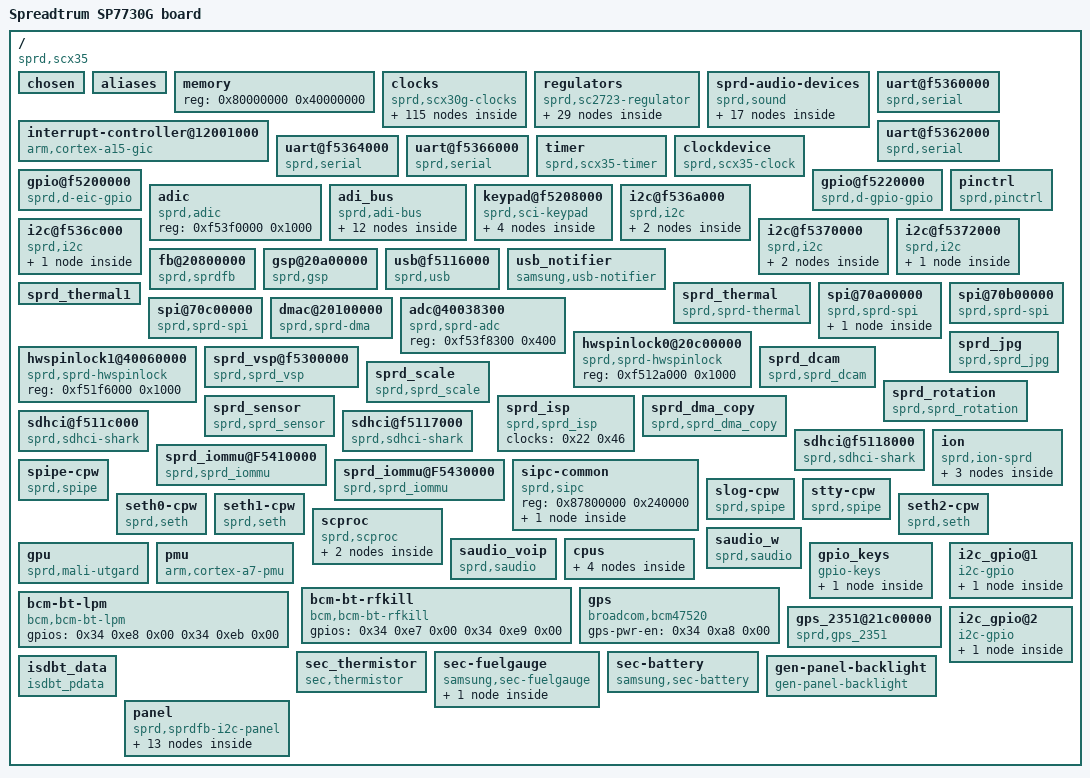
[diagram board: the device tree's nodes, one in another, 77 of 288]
/dts-v1/;

/memreserve/	0x0000000087800000 0x0000000000240000;
/memreserve/	0x0000000088000000 0x0000000001c00000;
/memreserve/	0x000000009eef4000 0x0000000000708000;
/memreserve/	0x000000009f5fc000 0x0000000000504000;
/ {
	#address-cells = <0x01>;
	#size-cells = <0x01>;
	compatible = "sprd,scx35";
	sprd,sc-id = <0x227e 0x02 0x20000>;
	interrupt-parent = <0x01>;
	model = "Spreadtrum SP7730G board";

	chosen {
		bootargs = "init=/init root=/dev/ram0 rw";
		linux,initrd-start = <0x85500000>;
		linux,initrd-end = <0x855a3212>;
	};

	aliases {
		serial0 = "/uart@f5360000";
		serial1 = "/uart@f5362000";
		serial2 = "/uart@f5364000";
		serial3 = "/uart@f5366000";
		i2c0 = "/i2c@f536a000";
		i2c1 = "/i2c@f536c000";
		i2c2 = "/i2c@f5370000";
		i2c3 = "/i2c@f5372000";
		lcd0 = "/fb@20800000";
		spi0 = "/spi@70a00000";
		spi1 = "/spi@70b00000";
		spi2 = "/spi@70c00000";
		hwspinlock0 = "/hwspinlock0@20c00000";
		hwspinlock1 = "/hwspinlock1@40060000";
		i2c_gpio6 = "/i2c_gpio@1";
		i2c_gpio7 = "/i2c_gpio@2";
	};

	memory {
		#address-cells = <0x01>;
		#size-cells = <0x01>;
		device_type = "memory";
		reg = <0x80000000 0x40000000>;
	};

	clocks {
		compatible = "sprd,scx30g-clocks";
		#address-cells = <0x01>;
		#size-cells = <0x01>;

		ext_26m {
			compatible = "sprd,fixed-clock";
			#clock-cells = <0x00>;
			clock-frequency = <0x18cba80>;
			clock-output-names = "ext_26m";
			linux,phandle = <0x08>;
			phandle = <0x08>;
		};

		ext_32k {
			compatible = "sprd,fixed-clock";
			#clock-cells = <0x00>;
			clock-frequency = <0x8000>;
			clock-output-names = "ext_32k";
			linux,phandle = <0x11>;
			phandle = <0x11>;
		};

		clk_mpll {
			compatible = "sprd,adjustable-pll-clock";
			#clock-cells = <0x00>;
			reg = <0x402e3070 0x7ff 0x402b0094 0x01>;
			clock-output-names = "clk_mpll";
			linux,phandle = <0x03>;
			phandle = <0x03>;
		};

		clk_dpll {
			compatible = "sprd,adjustable-pll-clock";
			#clock-cells = <0x00>;
			reg = <0x402e3074 0x7ff 0x402b0098 0x01>;
			clock-output-names = "clk_dpll";
			linux,phandle = <0x04>;
			phandle = <0x04>;
		};

		clk_tdpll {
			compatible = "sprd,adjustable-pll-clock";
			#clock-cells = <0x00>;
			reg = <0x402e3078 0x7ff 0x402b009c 0x01>;
			clock-output-names = "clk_tdpll";
			linux,phandle = <0x07>;
			phandle = <0x07>;
		};

		clk_wpll {
			compatible = "sprd,adjustable-pll-clock";
			#clock-cells = <0x00>;
			reg = <0x402e301c 0x7ff 0x402b00a0 0x01>;
			clock-output-names = "clk_wpll";
			linux,phandle = <0x02>;
			phandle = <0x02>;
		};

		clk_cpll {
			compatible = "sprd,adjustable-pll-clock";
			#clock-cells = <0x00>;
			reg = <0x402e307c 0x7ff 0x402b00a4 0x01>;
			clock-output-names = "clk_cpll";
			linux,phandle = <0x06>;
			phandle = <0x06>;
		};

		clk_wifipll {
			compatible = "sprd,adjustable-pll-clock";
			#clock-cells = <0x00>;
			reg = <0x402e3080 0x7ff 0x402b00a8 0x01>;
			clock-output-names = "clk_wifipll";
			linux,phandle = <0x05>;
			phandle = <0x05>;
		};

		clk_460m8 {
			compatible = "sprd,fixed-factor-clock";
			#clock-cells = <0x00>;
			clock-mult = <0x01>;
			clock-div = <0x02>;
			clocks = <0x02>;
			clock-output-names = "clk_460m8";
			linux,phandle = <0x21>;
			phandle = <0x21>;
		};

		clk_300m {
			compatible = "sprd,fixed-factor-clock";
			#clock-cells = <0x00>;
			clock-mult = <0x01>;
			clock-div = <0x03>;
			clocks = <0x03>;
			clock-output-names = "clk_300m";
			linux,phandle = <0x20>;
			phandle = <0x20>;
		};

		clk_37m5 {
			compatible = "sprd,fixed-factor-clock";
			#clock-cells = <0x00>;
			clock-mult = <0x01>;
			clock-div = <0x18>;
			clocks = <0x03>;
			clock-output-names = "clk_37m5";
			linux,phandle = <0x15>;
			phandle = <0x15>;
		};

		clk_66m_d {
			compatible = "sprd,fixed-factor-clock";
			#clock-cells = <0x00>;
			clock-mult = <0x01>;
			clock-div = <0x08>;
			clocks = <0x04>;
			clock-output-names = "clk_66m_d";
		};

		clk_51m2_w {
			compatible = "sprd,fixed-factor-clock";
			#clock-cells = <0x00>;
			clock-mult = <0x01>;
			clock-div = <0x12>;
			clocks = <0x02>;
			clock-output-names = "clk_51m2_w";
			linux,phandle = <0x14>;
			phandle = <0x14>;
		};

		clk_40m_wf1 {
			compatible = "sprd,fixed-factor-clock";
			#clock-cells = <0x00>;
			clock-mult = <0x01>;
			clock-div = <0x16>;
			clocks = <0x05>;
			clock-output-names = "clk_40m_wf1";
			linux,phandle = <0x16>;
			phandle = <0x16>;
		};

		clk_312m {
			compatible = "sprd,fixed-factor-clock";
			#clock-cells = <0x00>;
			clock-mult = <0x01>;
			clock-div = <0x02>;
			clocks = <0x06>;
			clock-output-names = "clk_312m";
			linux,phandle = <0x1b>;
			phandle = <0x1b>;
		};

		clk_208m {
			compatible = "sprd,fixed-factor-clock";
			#clock-cells = <0x00>;
			clock-mult = <0x01>;
			clock-div = <0x03>;
			clocks = <0x06>;
			clock-output-names = "clk_208m";
			linux,phandle = <0x1d>;
			phandle = <0x1d>;
		};

		clk_104m {
			compatible = "sprd,fixed-factor-clock";
			#clock-cells = <0x00>;
			clock-mult = <0x01>;
			clock-div = <0x06>;
			clocks = <0x06>;
			clock-output-names = "clk_104m";
		};

		clk_52m {
			compatible = "sprd,fixed-factor-clock";
			#clock-cells = <0x00>;
			clock-mult = <0x01>;
			clock-div = <0x0c>;
			clocks = <0x06>;
			clock-output-names = "clk_52m";
			linux,phandle = <0x13>;
			phandle = <0x13>;
		};

		clk_384m {
			compatible = "sprd,fixed-factor-clock";
			#clock-cells = <0x00>;
			clock-mult = <0x01>;
			clock-div = <0x02>;
			clocks = <0x07>;
			clock-output-names = "clk_384m";
			linux,phandle = <0x1c>;
			phandle = <0x1c>;
		};

		clk_256m {
			compatible = "sprd,fixed-factor-clock";
			#clock-cells = <0x00>;
			clock-mult = <0x01>;
			clock-div = <0x03>;
			clocks = <0x07>;
			clock-output-names = "clk_256m";
			linux,phandle = <0x1a>;
			phandle = <0x1a>;
		};

		clk_192m {
			compatible = "sprd,fixed-factor-clock";
			#clock-cells = <0x00>;
			clock-mult = <0x01>;
			clock-div = <0x04>;
			clocks = <0x07>;
			clock-output-names = "clk_192m";
			linux,phandle = <0x19>;
			phandle = <0x19>;
		};

		clk_153m6 {
			compatible = "sprd,fixed-factor-clock";
			#clock-cells = <0x00>;
			clock-mult = <0x01>;
			clock-div = <0x05>;
			clocks = <0x07>;
			clock-output-names = "clk_153m6";
			linux,phandle = <0x0c>;
			phandle = <0x0c>;
		};

		clk_128m {
			compatible = "sprd,fixed-factor-clock";
			#clock-cells = <0x00>;
			clock-mult = <0x01>;
			clock-div = <0x06>;
			clocks = <0x07>;
			clock-output-names = "clk_128m";
			linux,phandle = <0x0b>;
			phandle = <0x0b>;
		};

		clk_96m {
			compatible = "sprd,fixed-factor-clock";
			#clock-cells = <0x00>;
			clock-mult = <0x01>;
			clock-div = <0x08>;
			clocks = <0x07>;
			clock-output-names = "clk_96m";
			linux,phandle = <0x0a>;
			phandle = <0x0a>;
		};

		clk_76m8 {
			compatible = "sprd,fixed-factor-clock";
			#clock-cells = <0x00>;
			clock-mult = <0x01>;
			clock-div = <0x0a>;
			clocks = <0x07>;
			clock-output-names = "clk_76m8";
			linux,phandle = <0x0d>;
			phandle = <0x0d>;
		};

		clk_64m {
			compatible = "sprd,fixed-factor-clock";
			#clock-cells = <0x00>;
			clock-mult = <0x01>;
			clock-div = <0x0c>;
			clocks = <0x07>;
			clock-output-names = "clk_64m";
			linux,phandle = <0x10>;
			phandle = <0x10>;
		};

		clk_51m2 {
			compatible = "sprd,fixed-factor-clock";
			#clock-cells = <0x00>;
			clock-mult = <0x01>;
			clock-div = <0x0f>;
			clocks = <0x07>;
			clock-output-names = "clk_51m2";
			linux,phandle = <0x0f>;
			phandle = <0x0f>;
		};

		clk_48m {
			compatible = "sprd,fixed-factor-clock";
			#clock-cells = <0x00>;
			clock-mult = <0x01>;
			clock-div = <0x10>;
			clocks = <0x07>;
			clock-output-names = "clk_48m";
			linux,phandle = <0x12>;
			phandle = <0x12>;
		};

		clk_38m4 {
			compatible = "sprd,fixed-factor-clock";
			#clock-cells = <0x00>;
			clock-mult = <0x01>;
			clock-div = <0x14>;
			clocks = <0x07>;
			clock-output-names = "clk_38m4";
			linux,phandle = <0x0e>;
			phandle = <0x0e>;
		};

		clk_24m {
			compatible = "sprd,fixed-factor-clock";
			#clock-cells = <0x00>;
			clock-mult = <0x01>;
			clock-div = <0x20>;
			clocks = <0x07>;
			clock-output-names = "clk_24m";
			linux,phandle = <0x1f>;
			phandle = <0x1f>;
		};

		clk_12m {
			compatible = "sprd,fixed-factor-clock";
			#clock-cells = <0x00>;
			clock-mult = <0x01>;
			clock-div = <0x40>;
			clocks = <0x07>;
			clock-output-names = "clk_12m";
			linux,phandle = <0x1e>;
			phandle = <0x1e>;
		};

		clk_mcu {
			compatible = "sprd,composite-dev-clock";
			#clock-cells = <0x00>;
			reg = <0x20d03000 0x07 0x20d03000 0x70>;
			clocks = <0x08 0x04 0x06 0x07 0x05 0x02 0x03>;
			clock-output-names = "clk_mcu";
			linux,phandle = <0x09>;
			phandle = <0x09>;
		};

		clk_ca7_axi {
			compatible = "sprd,divider-clock";
			#clock-cells = <0x00>;
			reg = <0x20d03000 0x700>;
			clocks = <0x09>;
			clock-output-names = "clk_ca7_axi";
		};

		clk_ca7_dbg {
			compatible = "sprd,divider-clock";
			#clock-cells = <0x00>;
			reg = <0x20d03000 0x70000 0x20d00014 0x100>;
			clocks = <0x09>;
			clock-output-names = "clk_ca7_dbg";
		};

		clk_emc {
			compatible = "sprd,composite-dev-clock";
			#clock-cells = <0x00>;
			reg = <0x402d0024 0x03 0x402d0024 0x300>;
			clocks = <0x08 0x06 0x07 0x04>;
			clock-output-names = "clk_emc";
		};

		clk_pub_ahb {
			compatible = "sprd,muxed-clock";
			#clock-cells = <0x00>;
			reg = <0x402d0020 0x03>;
			clocks = <0x08 0x0a 0x0b 0x0c>;
			clock-output-names = "clk_pub_ahb";
		};

		clk_aon_apb {
			compatible = "sprd,composite-dev-clock";
			#clock-cells = <0x00>;
			reg = <0x402d0028 0x03 0x402d0028 0x300>;
			clocks = <0x08 0x0d 0x0a 0x0b>;
			clock-output-names = "clk_aon_apb";
			linux,phandle = <0x18>;
			phandle = <0x18>;
		};

		clk_adi {
			compatible = "sprd,muxed-clock";
			#clock-cells = <0x00>;
			reg = <0x402d0034 0x03 0x402e0000 0x10000>;
			clocks = <0x08 0x0e 0x0f 0x10>;
			clock-output-names = "clk_adi";
		};

		clk_aux0 {
			compatible = "sprd,composite-dev-clock";
			#clock-cells = <0x00>;
			reg = <0x402e3020 0x07 0x402e3020 0xf0000 0x402e0004 0x04>;
			clocks = <0x11 0x08 0x08 0x12 0x13 0x14 0x15 0x16>;
			clock-output-names = "clk_aux0";
		};

		clk_aux1 {
			compatible = "sprd,composite-dev-clock";
			#clock-cells = <0x00>;
			reg = <0x402e3020 0x70 0x402e3020 0xf00000 0x402e0004 0x08>;
			clocks = <0x11 0x08 0x08 0x12 0x13 0x14 0x15 0x16>;
			clock-output-names = "clk_aux1";
		};

		clk_aux2 {
			compatible = "sprd,composite-dev-clock";
			#clock-cells = <0x00>;
			reg = <0x402e3020 0x700 0x402e3020 0xf000000 0x402e0004 0x10>;
			clocks = <0x11 0x08 0x08 0x12 0x13 0x14 0x15 0x16>;
			clock-output-names = "clk_aux2";
		};

		clk_probe {
			compatible = "sprd,composite-dev-clock";
			#clock-cells = <0x00>;
			reg = <0x402e3020 0x7000 0x402e3020 0xf0000000 0x402e0004 0x20>;
			clocks = <0x11 0x08 0x08 0x12 0x13 0x14 0x15 0x16>;
			clock-output-names = "clk_probe";
		};

		clk_pwm0 {
			compatible = "sprd,muxed-clock";
			#clock-cells = <0x00>;
			reg = <0x402d0038 0x01 0x402e0000 0x10>;
			clocks = <0x11 0x08>;
			clock-output-names = "clk_pwm0";
		};

		clk_pwm1 {
			compatible = "sprd,muxed-clock";
			#clock-cells = <0x00>;
			reg = <0x402d003c 0x01 0x402e0000 0x20>;
			clocks = <0x11 0x08>;
			clock-output-names = "clk_pwm1";
		};

		clk_pwm2 {
			compatible = "sprd,muxed-clock";
			#clock-cells = <0x00>;
			reg = <0x402d0040 0x01 0x402e0000 0x40>;
			clocks = <0x11 0x08>;
			clock-output-names = "clk_pwm2";
		};

		clk_pwm3 {
			compatible = "sprd,muxed-clock";
			#clock-cells = <0x00>;
			reg = <0x402d0044 0x01 0x402e0000 0x80>;
			clocks = <0x11 0x08>;
			clock-output-names = "clk_pwm3";
		};

		clk_thm {
			compatible = "sprd,muxed-clock";
			#clock-cells = <0x00>;
			reg = <0x402d0048 0x01 0x402e0004 0x02>;
			clocks = <0x11 0x08>;
			clock-output-names = "clk_thm";
		};

		clk_efuse {
			compatible = "sprd,gate-clock";
			#clock-cells = <0x00>;
			reg = <0x402e0000 0x2000>;
			clocks = <0x08>;
			clock-output-names = "clk_efuse";
		};

		clk_mspi {
			compatible = "sprd,muxed-clock";
			#clock-cells = <0x00>;
			reg = <0x402d0054 0x03 0x402e0000 0x800000>;
			clocks = <0x08 0x13 0x0d 0x0a>;
			clock-output-names = "clk_mspi";
		};

		clk_i2c {
			compatible = "sprd,muxed-clock";
			#clock-cells = <0x00>;
			reg = <0x402d0058 0x03 0x402e0000 0x80000000>;
			clocks = <0x08 0x12 0x0f 0x0c>;
			clock-output-names = "clk_i2c";
		};

		clk_avs0 {
			compatible = "sprd,muxed-clock";
			#clock-cells = <0x00>;
			reg = <0x402d005c 0x03 0x402e0000 0x40>;
			clocks = <0x08 0x12 0x0f 0x0a>;
			clock-output-names = "clk_avs0";
		};

		clk_avs1 {
			compatible = "sprd,muxed-clock";
			#clock-cells = <0x00>;
			reg = <0x402d0060 0x03 0x402e0000 0x80>;
			clocks = <0x08 0x12 0x0f 0x0a>;
			clock-output-names = "clk_avs1";
		};

		clk_aud {
			compatible = "sprd,gate-clock";
			#clock-cells = <0x00>;
			reg = <0x402e0000 0x40000>;
			clocks = <0x08>;
			clock-output-names = "clk_aud";
		};

		clk_audif {
			compatible = "sprd,muxed-clock";
			#clock-cells = <0x00>;
			reg = <0x402d002c 0x03 0x402e0000 0x20000>;
			clocks = <0x08 0x0e 0x0f>;
			clock-output-names = "clk_audif";
		};

		clk_vbc {
			compatible = "sprd,gate-clock";
			#clock-cells = <0x00>;
			reg = <0x402e0000 0x80000>;
			clocks = <0x08>;
			clock-output-names = "clk_vbc";
		};

		clk_ca7_dap {
			compatible = "sprd,muxed-clock";
			#clock-cells = <0x00>;
			reg = <0x402d004c 0x03 0x402e0000 0x40000000>;
			clocks = <0x08 0x0d 0x0b 0x0c>;
			clock-output-names = "clk_ca7_dap";
		};

		clk_ca7_ts {
			compatible = "sprd,muxed-clock";
			#clock-cells = <0x00>;
			reg = <0x402d0050 0x03 0x402e0000 0x10000000>;
			clocks = <0x11 0x08 0x0b 0x0c>;
			clock-output-names = "clk_ca7_ts";
		};

		clk_fm_in {
			compatible = "sprd,fixed-clock";
			#clock-cells = <0x00>;
			clock-frequency = <0x3d09000>;
			clock-output-names = "clk_fm_in";
			linux,phandle = <0x17>;
			phandle = <0x17>;
		};

		clk_fm {
			compatible = "sprd,gate-clock";
			#clock-cells = <0x00>;
			reg = <0x402e0000 0x02>;
			clocks = <0x17>;
			clock-output-names = "clk_fm";
		};

		clk_disp_emc {
			compatible = "sprd,gate-clock";
			#clock-cells = <0x00>;
			reg = <0x402e0004 0x800>;
			clocks = <0x18>;
			clock-output-names = "clk_disp_emc";
			linux,phandle = <0x3b>;
			phandle = <0x3b>;
		};

		clk_zip_emc {
			compatible = "sprd,gate-clock";
			#clock-cells = <0x00>;
			reg = <0x402e0004 0x1000>;
			clocks = <0x18>;
			clock-output-names = "clk_zip_emc";
		};

		clk_gsp_emc {
			compatible = "sprd,gate-clock";
			#clock-cells = <0x00>;
			reg = <0x402e0004 0x2000>;
			clocks = <0x18>;
			clock-output-names = "clk_gsp_emc";
			linux,phandle = <0x3e>;
			phandle = <0x3e>;
		};

		clk_ap_ahb {
			compatible = "sprd,muxed-clock";
			#clock-cells = <0x00>;
			reg = <0x71200020 0x03>;
			clocks = <0x08 0x0d 0x0b 0x19>;
			clock-output-names = "clk_ap_ahb";
		};

		clk_ap_apb {
			compatible = "sprd,muxed-clock";
			#clock-cells = <0x00>;
			reg = <0x71200024 0x03>;
			clocks = <0x08 0x10 0x0a 0x0b>;
			clock-output-names = "clk_ap_apb";
		};

		clk_gsp {
			compatible = "sprd,muxed-clock";
			#clock-cells = <0x00>;
			reg = <0x71200028 0x03 0x20d00000 0x08>;
			clocks = <0x0a 0x0c 0x19 0x1a>;
			clock-output-names = "clk_gsp";
			linux,phandle = <0x3d>;
			phandle = <0x3d>;
		};

		clk_dispc0 {
			compatible = "sprd,composite-dev-clock";
			#clock-cells = <0x00>;
			reg = <0x7120002c 0x03 0x7120002c 0x700 0x20d00000 0x02>;
			clocks = <0x0c 0x19 0x1a 0x1b>;
			clock-output-names = "clk_dispc0";
			linux,phandle = <0x38>;
			phandle = <0x38>;
		};

		clk_dispc0_dbi {
			compatible = "sprd,composite-dev-clock";
			#clock-cells = <0x00>;
			reg = <0x71200030 0x03 0x71200030 0x700 0x20d00000 0x02>;
			clocks = <0x0b 0x0c 0x19 0x1a>;
			clock-output-names = "clk_dispc0_dbi";
			linux,phandle = <0x39>;
			phandle = <0x39>;
		};

		clk_dispc0_dpi {
			compatible = "sprd,composite-dev-clock";
			#clock-cells = <0x00>;
			reg = <0x71200034 0x03 0x71200034 0xff00 0x20d00000 0x02>;
			clocks = <0x0b 0x0c 0x19 0x1c>;
			clock-output-names = "clk_dispc0_dpi";
			linux,phandle = <0x3a>;
			phandle = <0x3a>;
		};

		clk_dispc1 {
			compatible = "sprd,composite-dev-clock";
			#clock-cells = <0x00>;
			reg = <0x71200038 0x03 0x71200038 0x700 0x20d00000 0x04>;
			clocks = <0x0c 0x19 0x1a 0x1b>;
			clock-output-names = "clk_dispc1";
		};

		clk_dispc1_dbi {
			compatible = "sprd,composite-dev-clock";
			#clock-cells = <0x00>;
			reg = <0x7120003c 0x03 0x7120003c 0x700 0x20d00000 0x04>;
			clocks = <0x0b 0x0c 0x19 0x1a>;
			clock-output-names = "clk_dispc1_dbi";
		};

		clk_dispc1_dpi {
			compatible = "sprd,composite-dev-clock";
			#clock-cells = <0x00>;
			reg = <0x71200040 0x03 0x71200040 0xff00 0x20d00000 0x04>;
			clocks = <0x0b 0x0c 0x19 0x1c>;
			clock-output-names = "clk_dispc1_dpi";
		};

		clk_nandc_ecc {
			compatible = "sprd,muxed-clock";
			#clock-cells = <0x00>;
			reg = <0x71200044 0x01 0x20d00000 0x80000 0x20d00000 0x20000>;
			clocks = <0x0c 0x19>;
			clock-output-names = "clk_nandc_ecc";
		};

		clk_nandc_2x {
			compatible = "sprd,composite-dev-clock";
			#clock-cells = <0x00>;
			reg = <0x20d03038 0x03 0x20d03038 0x0c 0x20d00000 0xe0000>;
			clocks = <0x1d 0x1a 0x1b 0x1c>;
			clock-output-names = "clk_nandc_2x";
		};

		clk_sdio0 {
			compatible = "sprd,composite-dev-clock";
			#clock-cells = <0x00>;
			reg = <0x71200048 0x03 0x71200048 0x700 0x20d00000 0x100>;
			clocks = <0x08 0x1a 0x1b 0x1c>;
			clock-output-names = "clk_sdio0";
			linux,phandle = <0x48>;
			phandle = <0x48>;
		};

		clk_sdio1 {
			compatible = "sprd,muxed-clock";
			#clock-cells = <0x00>;
			reg = <0x7120004c 0x03 0x20d00000 0x200>;
			clocks = <0x12 0x0d 0x0a 0x0b>;
			clock-output-names = "clk_sdio1";
			linux,phandle = <0x49>;
			phandle = <0x49>;
		};

		clk_sdio2 {
			compatible = "sprd,muxed-clock";
			#clock-cells = <0x00>;
			reg = <0x71200050 0x03 0x20d00000 0x400>;
			clocks = <0x12 0x0d 0x0a 0x0b>;
			clock-output-names = "clk_sdio2";
		};

		clk_emmc {
			compatible = "sprd,muxed-clock";
			#clock-cells = <0x00>;
			reg = <0x71200054 0x03 0x20d00000 0x800>;
			clocks = <0x08 0x1a 0x1b 0x1c>;
			clock-output-names = "clk_emmc";
			linux,phandle = <0x47>;
			phandle = <0x47>;
		};

		clk_gps {
			compatible = "sprd,muxed-clock";
			#clock-cells = <0x00>;
			reg = <0x71200058 0x01 0x20d00000 0x1000>;
			clocks = <0x10 0x0d>;
			clock-output-names = "clk_gps";
		};

		clk_usb_ref {
			compatible = "sprd,muxed-clock";
			#clock-cells = <0x00>;
			reg = <0x71200060 0x01 0x20d00000 0x10>;
			clocks = <0x1e 0x1f>;
			clock-output-names = "clk_usb_ref";
		};

		clk_uart0 {
			compatible = "sprd,composite-dev-clock";
			#clock-cells = <0x00>;
			reg = <0x71200064 0x03 0x71200064 0x700 0x71300000 0x2000>;
			clocks = <0x08 0x12 0x0f 0x0a>;
			clock-output-names = "clk_uart0";
		};

		clk_uart1 {
			compatible = "sprd,composite-dev-clock";
			#clock-cells = <0x00>;
			reg = <0x71200068 0x03 0x71200068 0x700 0x71300000 0x4000>;
			clocks = <0x08 0x12 0x0f 0x0a>;
			clock-output-names = "clk_uart1";
		};

		clk_uart2 {
			compatible = "sprd,composite-dev-clock";
			#clock-cells = <0x00>;
			reg = <0x7120006c 0x03 0x7120006c 0x700 0x71300000 0x8000>;
			clocks = <0x08 0x12 0x0f 0x0a>;
			clock-output-names = "clk_uart2";
		};

		clk_uart3 {
			compatible = "sprd,composite-dev-clock";
			#clock-cells = <0x00>;
			reg = <0x71200070 0x03 0x71200070 0x700 0x71300000 0x10000>;
			clocks = <0x08 0x12 0x0f 0x0a>;
			clock-output-names = "clk_uart3";
		};

		clk_uart4 {
			compatible = "sprd,composite-dev-clock";
			#clock-cells = <0x00>;
			reg = <0x71200074 0x03 0x71200074 0x700 0x71300000 0x20000>;
			clocks = <0x08 0x12 0x0f 0x0a>;
			clock-output-names = "clk_uart4";
		};

		clk_i2c0 {
			compatible = "sprd,composite-dev-clock";
			#clock-cells = <0x00>;
			reg = <0x71200078 0x03 0x71200078 0x700 0x71300000 0x100>;
			clocks = <0x08 0x12 0x0f 0x0c>;
			clock-output-names = "clk_i2c0";
		};

		clk_i2c1 {
			compatible = "sprd,composite-dev-clock";
			#clock-cells = <0x00>;
			reg = <0x7120007c 0x03 0x7120007c 0x700 0x71300000 0x200>;
			clocks = <0x08 0x12 0x0f 0x0c>;
			clock-output-names = "clk_i2c1";
		};

		clk_i2c2 {
			compatible = "sprd,composite-dev-clock";
			#clock-cells = <0x00>;
			reg = <0x71200080 0x03 0x71200080 0x700 0x71300000 0x400>;
			clocks = <0x08 0x12 0x0f 0x0c>;
			clock-output-names = "clk_i2c2";
		};

		clk_i2c3 {
			compatible = "sprd,composite-dev-clock";
			#clock-cells = <0x00>;
			reg = <0x71200084 0x03 0x71200084 0x700 0x71300000 0x800>;
			clocks = <0x08 0x12 0x0f 0x0c>;
			clock-output-names = "clk_i2c3";
		};

		clk_i2c4 {
			compatible = "sprd,composite-dev-clock";
			#clock-cells = <0x00>;
			reg = <0x71200088 0x03 0x71200088 0x700 0x71300000 0x1000>;
			clocks = <0x08 0x12 0x0f 0x0c>;
			clock-output-names = "clk_i2c4";
		};

		clk_spi0 {
			compatible = "sprd,composite-dev-clock";
			#clock-cells = <0x00>;
			reg = <0x7120008c 0x03 0x7120008c 0x700 0x71300000 0x20>;
			clocks = <0x08 0x0a 0x0c 0x19>;
			clock-output-names = "clk_spi0";
		};

		clk_spi1 {
			compatible = "sprd,composite-dev-clock";
			#clock-cells = <0x00>;
			reg = <0x71200090 0x03 0x71200090 0x700 0x71300000 0x40>;
			clocks = <0x08 0x0a 0x0c 0x19>;
			clock-output-names = "clk_spi1";
		};

		clk_spi2 {
			compatible = "sprd,composite-dev-clock";
			#clock-cells = <0x00>;
			reg = <0x71200094 0x03 0x71200094 0x700 0x71300000 0x80>;
			clocks = <0x08 0x0a 0x0c 0x19>;
			clock-output-names = "clk_spi2";
			linux,phandle = <0x3c>;
			phandle = <0x3c>;
		};

		clk_iis0 {
			compatible = "sprd,composite-dev-clock";
			#clock-cells = <0x00>;
			reg = <0x71200098 0x03 0x71200098 0x700 0x71300000 0x02>;
			clocks = <0x08 0x0b 0x0c>;
			clock-output-names = "clk_iis0";
		};

		clk_iis1 {
			compatible = "sprd,composite-dev-clock";
			#clock-cells = <0x00>;
			reg = <0x7120009c 0x03 0x7120009c 0x700 0x71300000 0x04>;
			clocks = <0x08 0x0b 0x0c>;
			clock-output-names = "clk_iis1";
		};

		clk_iis2 {
			compatible = "sprd,composite-dev-clock";
			#clock-cells = <0x00>;
			reg = <0x712000a0 0x03 0x712000a0 0x700 0x71300000 0x08>;
			clocks = <0x08 0x0b 0x0c>;
			clock-output-names = "clk_iis2";
		};

		clk_iis3 {
			compatible = "sprd,composite-dev-clock";
			#clock-cells = <0x00>;
			reg = <0x712000a4 0x03 0x712000a4 0x700 0x71300000 0x10>;
			clocks = <0x08 0x0b 0x0c>;
			clock-output-names = "clk_iis3";
		};

		clk_zipenc {
			compatible = "sprd,muxed-clock";
			#clock-cells = <0x00>;
			reg = <0x712000a8 0x03 0x20d00000 0x100000>;
			clocks = <0x0a 0x0c 0x19 0x1a>;
			clock-output-names = "clk_zipenc";
		};

		clk_zipdec {
			compatible = "sprd,muxed-clock";
			#clock-cells = <0x00>;
			reg = <0x712000ac 0x03 0x20d00000 0x200000>;
			clocks = <0x0a 0x0c 0x19 0x1a>;
			clock-output-names = "clk_zipdec";
		};

		clk_gpu_axi {
			compatible = "sprd,gate-clock";
			#clock-cells = <0x00>;
			reg = <0x402e0000 0x8000000 0x402b0021 0x2000000>;
			clocks = <0x18>;
			clock-output-names = "clk_gpu_axi";
			linux,phandle = <0x4b>;
			phandle = <0x4b>;
		};

		clk_gpu {
			compatible = "sprd,composite-dev-clock";
			#clock-cells = <0x00>;
			reg = <0x60100004 0x07 0x60100004 0x30>;
			clocks = <0x0c 0x1d 0x1a 0x20 0x1b 0x1c 0x21>;
			clock-output-names = "clk_gpu";
			linux,phandle = <0x4c>;
			phandle = <0x4c>;
		};

		clk_ccir_in {
			compatible = "sprd,fixed-clock";
			#clock-cells = <0x00>;
			clock-frequency = <0x3d09000>;
			clock-output-names = "clk_ccir_in";
			linux,phandle = <0x26>;
			phandle = <0x26>;
		};

		clk_mm {
			compatible = "sprd,gate-clock";
			#clock-cells = <0x00>;
			reg = <0x402e0000 0x2000000 0x402b001d 0x2000000>;
			clocks = <0x18>;
			clock-output-names = "clk_mm";
			linux,phandle = <0x22>;
			phandle = <0x22>;
		};

		clk_mm_ahb {
			compatible = "sprd,muxed-clock";
			#clock-cells = <0x00>;
			reg = <0x60e00020 0x03>;
			clocks = <0x08 0x0a 0x0b 0x0c>;
			clock-output-names = "clk_mm_ahb";
			mm-domain;
			linux,phandle = <0x24>;
			phandle = <0x24>;
		};

		clk_mm_axi {
			compatible = "sprd,gate-clock";
			#clock-cells = <0x00>;
			reg = <0x60d00008 0x80>;
			clocks = <0x22>;
			clock-output-names = "clk_mm_axi";
			mm-domain;
			linux,phandle = <0x23>;
			phandle = <0x23>;
		};

		clk_mm_mtx_axi {
			compatible = "sprd,gate-clock";
			#clock-cells = <0x00>;
			reg = <0x60d00008 0x100>;
			clocks = <0x23>;
			clock-output-names = "clk_mm_mtx_axi";
			mm-domain;
		};

		clk_mmu {
			compatible = "sprd,gate-clock";
			#clock-cells = <0x00>;
			reg = <0x60d00000 0x80>;
			clocks = <0x24>;
			clock-output-names = "clk_mmu";
			mm-domain;
			linux,phandle = <0x4a>;
			phandle = <0x4a>;
		};

		clk_mm_ckg {
			compatible = "sprd,gate-clock";
			#clock-cells = <0x00>;
			reg = <0x60d00000 0x40>;
			clocks = <0x24>;
			clock-output-names = "clk_mm_ckg";
			mm-domain;
		};

		clk_jpg {
			compatible = "sprd,muxed-clock";
			#clock-cells = <0x00>;
			reg = <0x60e00038 0x03 0x60d00008 0x40 0x60d00000 0x20>;
			clocks = <0x0d 0x0b 0x19 0x1a>;
			clock-output-names = "clk_jpg";
			mm-domain;
			linux,phandle = <0x41>;
			phandle = <0x41>;
		};

		clk_csi {
			compatible = "sprd,gate-clock";
			#clock-cells = <0x00>;
			reg = <0x60d00008 0x02 0x60d00000 0x10>;
			clocks = <0x24>;
			clock-output-names = "clk_csi";
			mm-domain;
			linux,phandle = <0x25>;
			phandle = <0x25>;
		};

		clk_dcam_mipi {
			compatible = "sprd,gate-clock";
			#clock-cells = <0x00>;
			reg = <0x60d00008 0x01>;
			clocks = <0x25>;
			clock-output-names = "clk_dcam_mipi";
			mm-domain;
			linux,phandle = <0x45>;
			phandle = <0x45>;
		};

		clk_vsp {
			compatible = "sprd,muxed-clock";
			#clock-cells = <0x00>;
			reg = <0x60e00030 0x03 0x60d00008 0x20 0x60d00000 0x08>;
			clocks = <0x0d 0x0b 0x19 0x1a>;
			clock-output-names = "clk_vsp";
			mm-domain;
			linux,phandle = <0x40>;
			phandle = <0x40>;
		};

		clk_isp {
			compatible = "sprd,muxed-clock";
			#clock-cells = <0x00>;
			reg = <0x60e00034 0x03 0x60d00008 0x10 0x60d00000 0x04>;
			clocks = <0x0d 0x0b 0x1a 0x1b>;
			clock-output-names = "clk_isp";
			mm-domain;
			linux,phandle = <0x46>;
			phandle = <0x46>;
		};

		clk_ccir {
			compatible = "sprd,muxed-clock";
			#clock-cells = <0x00>;
			reg = <0x60e00028 0x10000 0x60d00000 0x02>;
			clocks = <0x1f 0x26>;
			clock-output-names = "clk_ccir";
			mm-domain;
			linux,phandle = <0x44>;
			phandle = <0x44>;
		};

		clk_sensor {
			compatible = "sprd,composite-dev-clock";
			#clock-cells = <0x00>;
			reg = <0x60e00024 0x03 0x60e00024 0x700 0x60d00008 0x04>;
			clocks = <0x08 0x12 0x0d 0x0a>;
			clock-output-names = "clk_sensor";
			mm-domain;
			linux,phandle = <0x43>;
			phandle = <0x43>;
		};

		clk_dcam {
			compatible = "sprd,muxed-clock";
			#clock-cells = <0x00>;
			reg = <0x60e0002c 0x03 0x60d00008 0x08 0x60d00000 0x01>;
			clocks = <0x0d 0x0b 0x1a 0x1b>;
			clock-output-names = "clk_dcam";
			mm-domain;
			linux,phandle = <0x42>;
			phandle = <0x42>;
		};
	};

	regulators {
		compatible = "sprd,sc2723-regulator";
		#address-cells = <0x01>;
		#size-cells = <0x01>;

		dummy {
		};

		vddcore {
			regulator-name = "vddcore";
			reg = <0x40038810 0x200 0x40038a00 0x3ff 0x400388c0 0x01>;
			regulator-cal-channel = <0x40038888 0x4000 0x0d>;
			regulator-default-microvolt = <0xdbba0>;
			regulator-step-microvolt = <0xc35>;
			regulator-min-microvolt = <0x927c0>;
			regulator-max-microvolt = <0x2faf08>;
			regulator-microvolt-offset = <0x00>;
			default-on;
			dcdc;
		};

		vddarm {
			regulator-name = "vddarm";
			reg = <0x40038810 0x400 0x40038a04 0x3ff 0x400388c0 0x04>;
			regulator-cal-channel = <0x40038888 0x2000 0x0d>;
			regulator-default-microvolt = <0xdbba0>;
			regulator-step-microvolt = <0xc35>;
			regulator-min-microvolt = <0x927c0>;
			regulator-max-microvolt = <0x2faf08>;
			regulator-microvolt-offset = <0x00>;
			default-on;
			dcdc;
		};

		vddmem {
			regulator-name = "vddmem";
			reg = <0x40038810 0x800 0x40038a08 0x3ff 0x400388c0 0x08>;
			regulator-cal-channel = <0x40038888 0x6000 0x0d>;
			regulator-default-microvolt = <0x124f80>;
			regulator-step-microvolt = <0xc35>;
			regulator-min-microvolt = <0x927c0>;
			regulator-max-microvolt = <0x2faf08>;
			regulator-microvolt-offset = <0x00>;
			dcdc;
		};

		vddgen {
			regulator-name = "vddgen";
			reg = <0x40038810 0x1000 0x40038a0c 0x3ff 0x400388c0 0x10>;
			regulator-cal-channel = <0x40038888 0x8000 0x0d>;
			regulator-default-microvolt = <0x249f00>;
			regulator-step-microvolt = <0xc35>;
			regulator-min-microvolt = <0x927c0>;
			regulator-max-microvolt = <0x2faf08>;
			regulator-microvolt-offset = <0x00>;
			default-on;
			dcdc;
		};

		vddrf {
			regulator-name = "vddrf";
			reg = <0x40038810 0x2000 0x40038a1c 0x3ff 0x400388c0 0x20>;
			regulator-cal-channel = <0x40038888 0xa000 0x0d>;
			regulator-default-microvolt = <0x16e360>;
			regulator-step-microvolt = <0xc35>;
			regulator-min-microvolt = <0x927c0>;
			regulator-max-microvolt = <0x2faf08>;
			regulator-microvolt-offset = <0x00>;
			default-on;
			dcdc;
		};

		vddwpa {
			regulator-name = "vddwpa";
			reg = <0x40038814 0x4000 0x40038a10 0x07 0x00 0x00>;
			regulator-cal-channel = <0x40038888 0xe000 0x0d>;
			regulator-step-microvolt = <0xc35>;
			regulator-min-microvolt = <0x2faf08>;
			regulator-max-microvolt = <0x33e140>;
			regulator-microvolt-offset = <0x00>;
			dcdc;
		};

		vddcon {
			regulator-name = "vddcon";
			reg = <0x40038814 0x2000 0x40038a18 0x3ff 0x00 0x00>;
			regulator-cal-channel = <0x40038888 0xc000 0x0d>;
			regulator-default-microvolt = <0x186a00>;
			regulator-step-microvolt = <0xc35>;
			regulator-min-microvolt = <0x927c0>;
			regulator-max-microvolt = <0x2faf08>;
			regulator-microvolt-offset = <0x00>;
			dcdc;
		};

		vddrf0 {
			regulator-name = "vddrf0";
			reg = <0x40038810 0x100 0x40038818 0xff00 0x400388c0 0x800>;
			regulator-cal-channel = <0x40038844 0x04 0x15>;
			regulator-default-microvolt = <0x1b7740>;
			regulator-step-microvolt = <0x186a>;
			regulator-min-microvolt = <0x118c30>;
			regulator-max-microvolt = <0x29f630>;
			regulator-microvolt-offset = <0x00>;
			default-on;
		};

		vddemmccore {
			regulator-name = "vddemmccore";
			reg = <0x40038810 0x80 0x40038834 0xff00 0x400388c0 0x80>;
			regulator-cal-channel = <0x40038844 0x60 0x17>;
			regulator-default-microvolt = <0x2dc6c0>;
			regulator-step-microvolt = <0x2710>;
			regulator-min-microvolt = <0x124f80>;
			regulator-max-microvolt = <0x395f80>;
			regulator-microvolt-offset = <0x00>;
			default-on;
			linux,phandle = <0x37>;
			phandle = <0x37>;
		};

		vddgen1 {
			regulator-name = "vddgen1";
			reg = <0x40038810 0x40 0x40038824 0x7f00 0x400388c0 0x1000>;
			regulator-cal-channel = <0x40038844 0x05 0x15>;
			regulator-default-microvolt = <0x1b7740>;
			regulator-step-microvolt = <0x186a>;
			regulator-min-microvolt = <0x118c30>;
			regulator-max-microvolt = <0x1dc130>;
			regulator-microvolt-offset = <0x00>;
			default-on;
		};

		vddgen0 {
			regulator-name = "vddgen0";
			reg = <0x40038810 0x10 0x40038820 0x7f 0x400388c0 0x2000>;
			regulator-cal-channel = <0x40038844 0x06 0x15>;
			regulator-default-microvolt = <0x1b7740>;
			regulator-step-microvolt = <0x186a>;
			regulator-min-microvolt = <0x118c30>;
			regulator-max-microvolt = <0x1dc130>;
			regulator-microvolt-offset = <0x00>;
			default-on;
		};

		vdddcxo {
			regulator-name = "vdddcxo";
			reg = <0x40038810 0x20 0x40038838 0xff00 0x400388c0 0x100>;
			regulator-cal-channel = <0x40038844 0x80 0x17>;
			regulator-default-microvolt = <0x1b7740>;
			regulator-step-microvolt = <0x2710>;
			regulator-min-microvolt = <0x124f80>;
			regulator-max-microvolt = <0x395f80>;
			regulator-microvolt-offset = <0x00>;
			default-on;
		};

		vdd25 {
			regulator-name = "vdd25";
			reg = <0x40038810 0x08 0x40038840 0xff 0x400388c0 0x40>;
			regulator-cal-channel = <0x40038844 0x100 0x16>;
			regulator-default-microvolt = <0x2ab980>;
			regulator-step-microvolt = <0x2710>;
			regulator-min-microvolt = <0x124f80>;
			regulator-max-microvolt = <0x395f80>;
			regulator-microvolt-offset = <0x00>;
		};

		vdd28 {
			regulator-name = "vdd28";
			reg = <0x40038810 0x04 0x40038824 0xff 0x400388c0 0x200>;
			regulator-cal-channel = <0x40038844 0xc0 0x17>;
			regulator-default-microvolt = <0x2ab980>;
			regulator-step-microvolt = <0x2710>;
			regulator-min-microvolt = <0x124f80>;
			regulator-max-microvolt = <0x395f80>;
			regulator-microvolt-offset = <0x00>;
			default-on;
		};

		vdd18 {
			regulator-name = "vdd18";
			reg = <0x40038810 0x02 0x4003883c 0x7f00 0x400388c0 0x400>;
			regulator-cal-channel = <0x40038844 0x01 0x15>;
			regulator-default-microvolt = <0x1b7740>;
			regulator-step-microvolt = <0x186a>;
			regulator-min-microvolt = <0x118c30>;
			regulator-max-microvolt = <0x1dc130>;
			regulator-microvolt-offset = <0x00>;
			default-on;
			linux,phandle = <0x36>;
			phandle = <0x36>;
		};

		vddwifipa {
			regulator-name = "vddwifipa";
			reg = <0x40038814 0x800 0x40038818 0xff 0x00 0x00>;
			regulator-cal-channel = <0x40038844 0x20 0x17>;
			regulator-default-microvolt = <0x1b7740>;
			regulator-step-microvolt = <0x2710>;
			regulator-min-microvolt = <0x124f80>;
			regulator-max-microvolt = <0x395f80>;
			regulator-microvolt-offset = <0x00>;
			linux,phandle = <0x55>;
			phandle = <0x55>;
		};

		vddsdcore {
			regulator-name = "vddsdcore";
			reg = <0x40038814 0x400 0x40038830 0xff00 0x00 0x00>;
			regulator-cal-channel = <0x40038844 0xa0 0x17>;
			regulator-default-microvolt = <0x2dc6c0>;
			regulator-step-microvolt = <0x2710>;
			regulator-min-microvolt = <0x124f80>;
			regulator-max-microvolt = <0x395f80>;
			regulator-microvolt-offset = <0x00>;
		};

		vddsdio {
			regulator-name = "vddsdio";
			reg = <0x40038814 0x01 0x40038828 0xff 0x00 0x00>;
			regulator-cal-channel = <0x40038844 0x08 0x1d>;
			regulator-default-microvolt = <0x2dc6c0>;
			regulator-step-microvolt = <0x2710>;
			regulator-min-microvolt = <0x124f80>;
			regulator-max-microvolt = <0x395f80>;
			regulator-microvolt-offset = <0x00>;
			default-on;
			linux,phandle = <0x35>;
			phandle = <0x35>;
		};

		vddsim0 {
			regulator-name = "vddsim0";
			reg = <0x40038814 0x02 0x40038828 0xff00 0x00 0x00>;
			regulator-cal-channel = <0x40038844 0x500 0x16>;
			regulator-default-microvolt = <0x1b7740>;
			regulator-step-microvolt = <0x2710>;
			regulator-min-microvolt = <0x124f80>;
			regulator-max-microvolt = <0x395f80>;
			regulator-microvolt-offset = <0x00>;
		};

		vddsim1 {
			regulator-name = "vddsim1";
			reg = <0x40038814 0x04 0x4003882c 0xff 0x00 0x00>;
			regulator-cal-channel = <0x40038844 0x400 0x16>;
			regulator-default-microvolt = <0x1b7740>;
			regulator-step-microvolt = <0x2710>;
			regulator-min-microvolt = <0x124f80>;
			regulator-max-microvolt = <0x395f80>;
			regulator-microvolt-offset = <0x00>;
			linux,phandle = <0x54>;
			phandle = <0x54>;
		};

		vddsim2 {
			regulator-name = "vddsim2";
			reg = <0x40038814 0x08 0x4003882c 0xff00 0x00 0x00>;
			regulator-cal-channel = <0x40038844 0x300 0x16>;
			regulator-default-microvolt = <0x1b7740>;
			regulator-step-microvolt = <0x2710>;
			regulator-min-microvolt = <0x124f80>;
			regulator-max-microvolt = <0x395f80>;
			regulator-microvolt-offset = <0x00>;
		};

		vddcama {
			regulator-name = "vddcama";
			reg = <0x40038814 0x10 0x40038830 0xff 0x00 0x00>;
			regulator-cal-channel = <0x40038844 0x200 0x16>;
			regulator-default-microvolt = <0x2ab980>;
			regulator-step-microvolt = <0x2710>;
			regulator-min-microvolt = <0x124f80>;
			regulator-max-microvolt = <0x395f80>;
			regulator-microvolt-offset = <0x00>;
		};

		vddcamd {
			regulator-name = "vddcamd";
			reg = <0x40038814 0x20 0x4003881c 0x7f 0x00 0x00>;
			regulator-cal-channel = <0x40038844 0x02 0x15>;
			regulator-default-microvolt = <0x1b7740>;
			regulator-step-microvolt = <0x186a>;
			regulator-min-microvolt = <0x118c30>;
			regulator-max-microvolt = <0x1dc130>;
			regulator-microvolt-offset = <0x00>;
		};

		vddcamio {
			regulator-name = "vddcamio";
			reg = <0x40038814 0x40 0x4003881c 0x7f00 0x00 0x00>;
			regulator-cal-channel = <0x40038844 0x03 0x15>;
			regulator-default-microvolt = <0x1b7740>;
			regulator-step-microvolt = <0x186a>;
			regulator-min-microvolt = <0x118c30>;
			regulator-max-microvolt = <0x1dc130>;
			regulator-microvolt-offset = <0x00>;
		};

		vddcammot {
			regulator-name = "vddcammot";
			reg = <0x40038814 0x80 0x40038834 0xff 0x00 0x00>;
			regulator-cal-channel = <0x40038844 0x40 0x17>;
			regulator-default-microvolt = <0x2ab980>;
			regulator-step-microvolt = <0x2710>;
			regulator-min-microvolt = <0x124f80>;
			regulator-max-microvolt = <0x395f80>;
			regulator-microvolt-offset = <0x00>;
		};

		vddusb {
			regulator-name = "vddusb";
			reg = <0x40038814 0x100 0x4003883c 0xff 0x00 0x00>;
			regulator-cal-channel = <0x40038844 0x10 0x1d>;
			regulator-default-microvolt = <0x325aa0>;
			regulator-step-microvolt = <0x2710>;
			regulator-min-microvolt = <0x124f80>;
			regulator-max-microvolt = <0x395f80>;
			regulator-microvolt-offset = <0x00>;
			linux,phandle = <0x3f>;
			phandle = <0x3f>;
		};

		vddkpled {
			regulator-name = "vddkpled";
			reg = <0x400388f4 0x100 0x400388f4 0xff 0x00 0x00>;
			regulator-cal-channel = <0x400388f8 0x3000 0x18>;
			regulator-default-microvolt = <0x325aa0>;
			regulator-step-microvolt = <0x2710>;
			regulator-min-microvolt = <0x124f80>;
			regulator-max-microvolt = <0x395f80>;
			regulator-microvolt-offset = <0x00>;
		};

		vddvibr {
			regulator-name = "vddvibr";
			reg = <0x400388f8 0x100 0x400388f8 0xff 0x00 0x00>;
			regulator-cal-channel = <0x400388f8 0x2000 0x18>;
			regulator-default-microvolt = <0x2dc6c0>;
			regulator-step-microvolt = <0x2710>;
			regulator-min-microvolt = <0x124f80>;
			regulator-max-microvolt = <0x395f80>;
			regulator-microvolt-offset = <0x00>;
		};
	};

	sprd-audio-devices {
		compatible = "sprd,sound";
		#address-cells = <0x01>;
		#size-cells = <0x01>;

		sprd-codec {
			compatible = "sprd,sprd-codec";
			status = "okay";
			sprd,def_da_fs = <0xac44>;
			sprd,ap_irq = <0xa4>;
			sprd,dp_irq = <0x34>;
			sprd,audio_power_ver = <0x04>;
			linux,phandle = <0x29>;
			phandle = <0x29>;
		};

		sprd-codec-v3 {
			compatible = "sprd,sprd-codec-v3";
			status = "disable";
			sprd,def_da_fs = <0xac44>;
			sprd,ap_irq = <0xa4>;
			sprd,dp_irq = <0x34>;
			linux,phandle = <0x2b>;
			phandle = <0x2b>;
		};

		sprd-codec-v1 {
			compatible = "sprd,sprd-codec-v1";
			status = "disable";
			sprd,def_da_fs = <0xac44>;
			sprd,ap_irq = <0x67>;
			sprd,dp_irq = <0x3f>;
		};

		null-codec {
			compatible = "sprd,null-codec";
			linux,phandle = <0x30>;
			phandle = <0x30>;
		};

		vbc-r2p0 {
			compatible = "sprd,vbc-r2p0";
			status = "okay";
			linux,phandle = <0x28>;
			phandle = <0x28>;
		};

		vbc-r1p0 {
			compatible = "sprd,vbc-r1p0";
			status = "disable";
		};

		vaudio {
			compatible = "sprd,vaudio";
			linux,phandle = <0x27>;
			phandle = <0x27>;
		};

		bt-i2s-config {
			sprd,def_pcm_config;
		};

		fm-i2s-config {
		};

		i2s@0 {
			compatible = "sprd,i2s";
			status = "okay";
			sprd,dai_name = "i2s_bt_sco0";
			sprd,id = <0x00>;
			sprd,hw_port = <0x00>;
			sprd,base = <0x70d00000 0xf537c000>;
			sprd,dma_rx_no = <0x03>;
			sprd,dma_tx_no = <0x04>;
			linux,phandle = <0x2c>;
			phandle = <0x2c>;
		};

		i2s@1 {
			compatible = "sprd,i2s";
			status = "okay";
			sprd,dai_name = "i2s_bt_sco1";
			sprd,id = <0x01>;
			sprd,hw_port = <0x01>;
			sprd,base = <0x70e00000 0xf5380000>;
			sprd,dma_rx_no = <0x05>;
			sprd,dma_tx_no = <0x06>;
			linux,phandle = <0x2d>;
			phandle = <0x2d>;
		};

		i2s@2 {
			compatible = "sprd,i2s";
			status = "okay";
			sprd,dai_name = "i2s_bt_sco2";
			sprd,id = <0x02>;
			sprd,hw_port = <0x02>;
			sprd,base = <0x70f00000 0xf5382000>;
			sprd,dma_rx_no = <0x07>;
			sprd,dma_tx_no = <0x08>;
			linux,phandle = <0x2e>;
			phandle = <0x2e>;
		};

		i2s@3 {
			compatible = "sprd,i2s";
			status = "okay";
			sprd,dai_name = "i2s_bt_sco3";
			sprd,id = <0x03>;
			sprd,hw_port = <0x03>;
			sprd,base = <0x71000000 0xf5384000>;
			sprd,dma_rx_no = <0x09>;
			sprd,dma_tx_no = <0x0a>;
			linux,phandle = <0x2f>;
			phandle = <0x2f>;
		};

		sprd-pcm-audio {
			compatible = "sprd,sprd-pcm";
			linux,phandle = <0x2a>;
			phandle = <0x2a>;
		};

		sound@0 {
			compatible = "sprd,vbc-r2p0-sprd-codec";
			sprd,model = "sprdphone";
			sprd,vaudio = <0x27>;
			sprd,vbc = <0x28>;
			sprd,codec = <0x29>;
			sprd,pcm = <0x2a>;
		};

		sound@1 {
			compatible = "sprd,vbc-r2p0-sprd-codec-v3";
			sprd,model = "sprdphone";
			sprd,vaudio = <0x27>;
			sprd,vbc = <0x28>;
			sprd,codec = <0x2b>;
			sprd,pcm = <0x2a>;
		};

		sound@2 {
			compatible = "sprd,i2s-null-codec";
			sprd,model = "all-i2s";
			sprd,i2s = <0x2c 0x2d 0x2e 0x2f>;
			sprd,codec = <0x30>;
			sprd,pcm = <0x2a>;
		};
	};

	interrupt-controller@12001000 {
		compatible = "arm,cortex-a15-gic\0arm,cortex-a9-gic";
		#interrupt-cells = <0x03>;
		#address-cells = <0x00>;
		interrupt-controller;
		reg = <0x12001000 0x1000 0x12002000 0x1000>;
		linux,phandle = <0x01>;
		phandle = <0x01>;
	};

	uart@f5360000 {
		compatible = "sprd,serial";
		interrupts = <0x00 0x02 0x00>;
		reg = <0xf5360000 0x1000>;
		clock-names = "clk_uart0";
		clocks = <0x31 0x3c>;
		sprdclk = <0x2dc6c00>;
		sprdwaketype = "BT_RTS_HIGH_WHEN_SLEEP";
	};

	uart@f5362000 {
		compatible = "sprd,serial";
		interrupts = <0x00 0x03 0x00>;
		reg = <0xf5362000 0x1000>;
		clock-names = "clk_uart1";
		clocks = <0x31 0x3d>;
		sprdclk = <0x18cba80>;
		sprdwaketype = "BT_RTS_HIGH_WHEN_SLEEP";
	};

	uart@f5364000 {
		compatible = "sprd,serial";
		interrupts = <0x00 0x04 0x00>;
		reg = <0xf5364000 0x1000>;
		clock-names = "clk_uart2";
		clocks = <0x31 0x3e>;
		sprdclk = <0x18cba80>;
		sprdwaketype = "BT_RTS_HIGH_WHEN_SLEEP";
	};

	uart@f5366000 {
		compatible = "sprd,serial";
		interrupts = <0x00 0x05 0x00>;
		reg = <0xf5366000 0x1000>;
		clock-names = "clk_uart3";
		clocks = <0x31 0x3f>;
		sprdclk = <0x18cba80>;
		sprdwaketype = "BT_RTS_HIGH_WHEN_SLEEP";
	};

	timer {
		compatible = "sprd,scx35-timer";
		reg = <0xf5204000 0x1000 0xf51f4000 0x1000 0xf5202000 0x1000 0xf5292000 0x1000 0xf5294000 0x1000>;
		interrupts = <0x00 0x76 0x00 0x00 0x1c 0x00 0x00 0x1d 0x00 0x00 0x77 0x00 0x00 0x79 0x00>;
	};

	clockdevice {
		compatible = "sprd,scx35-clock";
		#clock-cells = <0x01>;
		linux,phandle = <0x31>;
		phandle = <0x31>;
	};

	gpio@f5200000 {
		compatible = "sprd,d-eic-gpio";
		reg = <0xf5200000 0x1000>;
		gpio-controller;
		interrupt-controller;
		#interrupt-cells = <0x02>;
		#gpio-cells = <0x02>;
		gpiobase = <0x120>;
		ngpios = <0x10>;
		interrupts = <0x00 0x25 0x00>;
	};

	gpio@f5220000 {
		compatible = "sprd,d-gpio-gpio";
		reg = <0xf5220000 0x1000>;
		gpio-controller;
		interrupt-controller;
		#interrupt-cells = <0x02>;
		#gpio-cells = <0x02>;
		gpiobase = <0x00>;
		ngpios = <0x100>;
		interrupts = <0x00 0x23 0x00>;
		linux,phandle = <0x34>;
		phandle = <0x34>;
	};

	adic {
		compatible = "sprd,adic";
		reg = <0xf53f0000 0x1000>;
	};

	pinctrl {
		compatible = "sprd,pinctrl";
		reg = <0xf5224000 0x1000>;
		pwr_domain = "vdd28\0vdd28\0vddsim0\0vddsim1\0vddsim2\0vddsdcore\0vdd18\0vddwifipa";
		ctrl_desc = <0x10 0x00 0x01 0x10 0x01 0x01 0x10 0x02 0x01 0x10 0x03 0x01 0x10 0x04 0x01 0x10 0x05 0x01 0x10 0x06 0x01 0x10 0x07 0x01>;
	};

	adi_bus {
		compatible = "sprd,adi-bus";
		interrupts = <0x00 0x26 0x00>;
		reg = <0xf53f8000 0x1000>;
		interrupt-controller;
		sprd,irqnums = <0x0b>;
		#interrupt-cells = <0x02>;
		#address-cells = <0x01>;
		#size-cells = <0x01>;
		ranges = <0x40 0xf53f8040 0x40 0x80 0xf53f8080 0x80 0x100 0xf53f8100 0x80 0x480 0xf53f8480 0x80>;
		linux,phandle = <0x32>;
		phandle = <0x32>;

		watchdog@40 {
			compatible = "sprd,watchdog";
			reg = <0x40 0x40>;
			interrupts = <0x03 0x00>;
		};

		rtc@80 {
			compatible = "sprd,rtc";
			reg = <0x80 0x80>;
			interrupts = <0x02 0x00>;
		};

		gpio@100 {
			compatible = "sprd,a-eic-gpio";
			reg = <0x100 0x80>;
			gpio-controller;
			interrupt-controller;
			#interrupt-cells = <0x02>;
			#gpio-cells = <0x02>;
			gpiobase = <0x130>;
			ngpios = <0x10>;
			interrupt-parent = <0x32>;
			interrupts = <0x05 0x00>;
			linux,phandle = <0x33>;
			phandle = <0x33>;
		};

		gpio@480 {
			compatible = "sprd,a-gpio-gpio";
			reg = <0x480 0x80>;
			gpio-controller;
			interrupt-controller;
			#interrupt-cells = <0x02>;
			#gpio-cells = <0x02>;
			gpiobase = <0x100>;
			ngpios = <0x20>;
			interrupt-parent = <0x32>;
			interrupts = <0x01 0x00>;
		};

		headset_detect {
			compatible = "sprd,headset-detect";
			gpio_switch = <0x00>;
			gpio_detect = <0xed>;
			gpio_button = <0xef>;
			irq_trigger_level_detect = <0x00>;
			irq_trigger_level_button = <0x00>;
			adc_threshold_3pole_detect = <0x6a4>;
			adc_threshold_4pole_detect = <0xa8c>;
			irq_threshold_buttont = <0x01>;
			voltage_headmicbias = <0x2dc6c0>;
			nbuttons = <0x03>;

			headset_buttons_media {
				adc_min = <0x00>;
				adc_max = <0xbe>;
				code = <0xe2>;
				type = <0x00>;
			};

			headset_buttons_up {
				adc_min = <0xbf>;
				adc_max = <0x15b>;
				code = <0x73>;
				type = <0x00>;
			};

			headset_buttons_down {
				adc_min = <0x15c>;
				adc_max = <0x2f8>;
				code = <0x72>;
				type = <0x00>;
			};
		};

		headset_sprd_sc2723 {
			compatible = "sprd,headset_sprd_sc2723";
			gpio_switch = <0x00>;
			gpio_detect = <0xed>;
			gpio_button = <0xef>;
			irq_trigger_level_detect = <0x00>;
			irq_trigger_level_button = <0x00>;
			adc_threshold_3pole_detect = <0x432>;
			adc_threshold_4pole_detect = <0xc1c>;
			irq_threshold_buttont = <0x01>;
			voltage_headmicbias = <0x2dc6c0>;
			nbuttons = <0x03>;

			headset_buttons_media {
				adc_min = <0x00>;
				adc_max = <0xc8>;
				code = <0xe2>;
				type = <0x00>;
			};

			headset_buttons_up {
				adc_min = <0xc9>;
				adc_max = <0x186>;
				code = <0x73>;
				type = <0x00>;
			};

			headset_buttons_down {
				adc_min = <0x187>;
				adc_max = <0x35c>;
				code = <0x72>;
				type = <0x00>;
			};
		};
	};

	keypad@f5208000 {
		compatible = "sprd,sci-keypad";
		reg = <0xf5208000 0x1000>;
		gpios = <0x33 0x02 0x00>;
		interrupts = <0x00 0x24 0x00>;
		sprd,keypad-num-rows = <0x02>;
		sprd,keypad-num-columns = <0x03>;
		sprd,keypad-rows-choose-hw = <0x30000>;
		sprd,keypad-cols-choose-hw = <0x700>;
		sprd,debounce_time = <0x1388>;
		linux,keypad-no-autorepeat;
		#sprd,support_long_key;

		key_volume_down {
			keypad,row = <0x01>;
			keypad,column = <0x00>;
			linux,code = <0x72>;
		};

		key_volume_up {
			keypad,row = <0x00>;
			keypad,column = <0x00>;
			linux,code = <0x73>;
		};

		key_volume_up1 {
			keypad,row = <0x00>;
			keypad,column = <0x02>;
			linux,code = <0x73>;
		};

		key_home {
			keypad,row = <0x00>;
			keypad,column = <0x01>;
			linux,code = <0x66>;
		};
	};

	i2c@f536a000 {
		compatible = "sprd,i2c";
		interrupts = <0x00 0x0b 0x00>;
		reg = <0xf536a000 0x1000>;
		#address-cells = <0x01>;
		#size-cells = <0x00>;

		sensor_main@0x3c {
			compatible = "sprd,sensor_main";
			reg = <0x3c>;
		};

		sensor_sub@0x21 {
			compatible = "sprd,sensor_sub";
			reg = <0x21>;
		};
	};

	i2c@f536c000 {
		compatible = "sprd,i2c";
		interrupts = <0x00 0x0c 0x00>;
		reg = <0xf536c000 0x1000>;
		#address-cells = <0x01>;
		#size-cells = <0x00>;

		bt532_ts@20 {
			compatible = "Zinitix,bt532_ts";
			reg = <0x20>;
			gpios = <0x34 0x52 0x00>;
			bt532,x_resolution = [02 57];
			bt532,y_resolution = [03 ff];
			bt532,orientation = [00];
			bt532,page_size = [00 80];
			tsp_vdd_supply_type = <0x01>;
		};
	};

	i2c@f5370000 {
		compatible = "sprd,i2c";
		interrupts = <0x00 0x0d 0x00>;
		reg = <0xf5370000 0x1000>;
		#address-cells = <0x01>;
		#size-cells = <0x00>;
		status = "okay";

		k2hh@1D {
			compatible = "stm,k2hh";
			reg = <0x1d>;
			interrupt-parent = <0x34>;
			interrupts = <0xa4 0x00>;
			stm,irq_gpio = <0x34 0xa4 0x00>;
			stm,reg_vdd-supply = <0x35>;
			stm,reg_vio-supply = <0x36>;
			stm,axis_map_x = <0x01>;
			stm,axis_map_y = <0x00>;
			stm,axis_map_z = <0x02>;
			stm,negate_x = <0x00>;
			stm,negate_y = <0x01>;
			stm,negate_z = <0x01>;
			stm,poll_interval = <0x64>;
			stm,min_interval = <0x02>;
		};

		sx9500-i2c@28 {
			compatible = "sx9500-i2c";
			reg = <0x28>;
			sx9500-i2c,vdd-supply = <0x37>;
			sx9500-i2c,nirq-gpio = <0x34 0xa7 0x00>;
		};
	};

	i2c@f5372000 {
		compatible = "sprd,i2c";
		interrupts = <0x00 0x0e 0x00>;
		reg = <0xf5372000 0x1000>;
		#address-cells = <0x01>;
		#size-cells = <0x00>;

		bridge@64 {
			compatible = "sprd_panel,i2c";
			reg = <0x64>;
		};
	};

	fb@20800000 {
		compatible = "sprd,sprdfb";
		reg = <0xf5122000 0x1000 0xf5146000 0x1000>;
		interrupts = <0x00 0x2e 0x00 0x00 0x30 0x00 0x00 0x31 0x00>;
		clock-names = "dispc_clk_parent\0dispc_dbi_clk_parent\0dispc_dpi_clk_parent\0dispc_emc_clk_parent\0dispc_clk\0dispc_dbi_clk\0dispc_dpi_clk\0dispc_emc_clk\0fb_spi_clock\0fb_spi_clock_parent";
		clocks = <0x1a 0x1a 0x1c 0x18 0x38 0x39 0x3a 0x3b 0x3c 0x08>;
		clock-src = <0xf424000 0xf424000 0x16e36000>;
		dpi_clk_div = <0x07>;
		sprd,fb_use_reservemem;
		sprd,fb_mem = <0x9eef4000 0x708000>;
	};

	gsp@20a00000 {
		compatible = "sprd,gsp";
		reg = <0xf5126000 0x1000>;
		interrupts = <0x00 0x33 0x00>;
		clock-names = "clk_gsp\0clk_gsp_emc\0clk_gsp_parent\0clk_aon_apb";
		clocks = <0x3d 0x3e 0x1a 0x18>;
		gsp_mmu_ctrl_base = <0xf5418000>;
	};

	usb@f5116000 {
		compatible = "sprd,usb";
		interrupts = <0x00 0x37 0x00>;
		reg = <0xf5116000 0x1000>;
		usb-supply = <0x3f>;
		#address-cells = <0x01>;
		#size-cells = <0x00>;
		ngpios = <0x02>;
		gpios = <0x33 0x00 0x00 0x34 0x48 0x00>;
	};

	usb_notifier {
		compatible = "samsung,usb-notifier";
		booster-name = "tps61256_booster";
		booster-gpio = <0x34 0xec 0x00>;
	};

	sprd_thermal {
		compatible = "sprd,sprd-thermal";
		id = <0x00>;
		interrupts = <0x00 0x1a 0x00>;
		reg = <0xf5260000 0x1000>;
		trip_points_active = <0x50 0x58 0x64>;
		trip_points_lowoff = <0x48 0x48 0x51>;
		trip_points_critical = <0x6e>;
		trip_num = <0x04>;
	};

	sprd_thermal1 {
		compatiable = "sprd,sprd-thermal";
		id = <0x01>;
		interrupt-parent = <0x32>;
		interrupts = <0x09 0x00>;
		reg = <0xf53f8280 0x1000>;
		trip_points_active = <0x5a>;
		trip_points_lowoff = <0x51>;
		trip_points_critical = <0x72>;
		trip_num = <0x02>;
	};

	spi@70a00000 {
		compatible = "sprd,sprd-spi";
		interrupts = <0x00 0x07 0x00>;
		reg = <0xf5376000 0x1000>;
		clock-names = "clk_spi0";
		#address-cells = <0x01>;
		#size-cells = <0x00>;

		isdbt@0 {
			compatible = "isdbt_spi_comp";
			reg = <0x00>;
			spi-max-frequency = <0x124f800>;
		};
	};

	spi@70b00000 {
		compatible = "sprd,sprd-spi";
		interrupts = <0x00 0x08 0x00>;
		reg = <0xf5378000 0x1000>;
		clock-names = "clk_spi1";
		#address-cells = <0x01>;
		#size-cells = <0x00>;
	};

	spi@70c00000 {
		compatible = "sprd,sprd-spi";
		interrupts = <0x00 0x09 0x00>;
		reg = <0xf537a000 0x1000>;
		clock-names = "clk_spi2";
		#address-cells = <0x01>;
		#size-cells = <0x00>;
	};

	dmac@20100000 {
		compatible = "sprd,sprd-dma";
		interrupts = <0x00 0x32 0x00>;
		reg = <0xf5112000 0x4000>;
	};

	adc@40038300 {
		compatible = "sprd,sprd-adc";
		reg = <0xf53f8300 0x400>;
	};

	hwspinlock0@20c00000 {
		compatible = "sprd,sprd-hwspinlock";
		reg = <0xf512a000 0x1000>;
	};

	hwspinlock1@40060000 {
		compatible = "sprd,sprd-hwspinlock";
		reg = <0xf51f6000 0x1000>;
	};

	sprd_vsp@f5300000 {
		compatible = "sprd,sprd_vsp";
		reg = <0xf5300000 0xc000>;
		interrupts = <0x00 0x2b 0x00>;
		clock-names = "clk_mm_i\0clk_vsp";
		clocks = <0x22 0x40>;
	};

	sprd_jpg {
		compatible = "sprd,sprd_jpg";
		reg = <0xf5320000 0x8000>;
		interrupts = <0x00 0x2a 0x00>;
		clock-names = "clk_mm_i\0clk_jpg";
		clocks = <0x22 0x41>;
	};

	sprd_dcam {
		compatible = "sprd,sprd_dcam";
		interrupts = <0x00 0x2d 0x00>;
		reg = <0xf52f0000 0x100000>;
		clock-names = "clk_mm_i\0clk_dcam";
		clocks = <0x22 0x42>;
	};

	sprd_scale {
		compatible = "sprd,sprd_scale";
	};

	sprd_rotation {
		compatible = "sprd,sprd_rotation";
	};

	sprd_sensor {
		compatible = "sprd,sprd_sensor";
		clock-names = "clk_mm_i\0clk_sensor\0clk_ccir\0clk_dcam\0clk_dcam_mipi";
		clocks = <0x22 0x43 0x44 0x42 0x45>;
		gpios = <0x34 0xba 0x00 0x34 0xbc 0x00 0x34 0xee 0x00 0x34 0xbb 0x00>;
	};

	sprd_isp {
		compatible = "sprd,sprd_isp";
		clock-names = "clk_mm_i\0clk_isp";
		clocks = <0x22 0x46>;
	};

	sprd_dma_copy {
		compatible = "sprd,sprd_dma_copy";
	};

	sdhci@f511c000 {
		compatible = "sprd,sdhci-shark";
		interrupts = <0x00 0x3c 0x00>;
		reg = <0xf511c000 0x1000>;
		id = <0x03>;
		bus-width = <0x08>;
		max-frequency = <0x16e36000>;
		keep-power-in-suspend = <0x01>;
		non-removable = <0x01>;
		sdhci-cap-1v8-ddr;
		sdhci-cap2-hc-erase-sz;
		sdhci-cap2-cache-ctrl;
		host-caps-mask = <0x3000000>;
		vdd-vmmc = "vddemmccore";
		vdd-vqmmc = "vddgen1";
		emmc-signal-supply = <0x37>;
		vdd-level = <0x124f80 0x13d620 0x16e360 0x1b7740>;
		clock-names = "clk_emmc";
		clocks = <0x47 0x1c>;
		enb-bit = <0x800>;
		rst-bit = <0x4000>;
		write-delay = <0x08>;
		read-pos-delay = <0x04>;
		read-neg-delay = <0x04>;
		keep-power = <0x00>;
		runtime = <0x01>;
	};

	sdhci@f5117000 {
		compatible = "sprd,sdhci-shark";
		interrupts = <0x00 0x39 0x00>;
		reg = <0xf5117000 0x1000>;
		id = <0x00>;
		bus-width = <0x04>;
		max-frequency = <0x16e36000>;
		keep-power-in-suspend = <0x01>;
		sdhci-cap2-hc-erase-sz;
		sdhci-cap2-cache-ctrl;
		host-caps-mask = <0x5000000>;
		vdd-vmmc = "vddsdcore";
		vdd-vqmmc = "vddsdcore";
		vdd-level = <0x00 0x00 0x1b7740 0x2dc6c0>;
		pinmap-offset = <0x184>;
		d3-gpio = <0x64>;
		d3-index = <0x00>;
		sd-func = <0x00>;
		gpio-func = <0x03>;
		cd-gpios = <0x47>;
		clock-names = "clk_sdio0";
		clocks = <0x48 0x1c>;
		enb-bit = <0x100>;
		rst-bit = <0x800>;
		keep-power = <0x00>;
		runtime = <0x01>;
	};

	sdhci@f5118000 {
		compatible = "sprd,sdhci-shark";
		interrupts = <0x00 0x3a 0x00>;
		reg = <0xf5118000 0x1000>;
		id = <0x01>;
		bus-width = <0x04>;
		max-frequency = <0x5b8d800>;
		keep-power-in-suspend = <0x01>;
		cap-power-off-card = <0x01>;
		clock-names = "clk_sdio1";
		clocks = <0x49 0x0a>;
		enb-bit = <0x200>;
		rst-bit = <0x1000>;
		keep-power = <0x00>;
		runtime = <0x01>;
	};

	ion {
		compatible = "sprd,ion-sprd";
		#address-cells = <0x01>;
		#size-cells = <0x00>;

		sprd,ion-heap@1 {
			reg = <0x01>;
			reg-names = "ion_heap_system";
			sprd,ion-heap-type = <0x00>;
			sprd,ion-heap-mem = <0x00 0x00>;
		};

		sprd,ion-heap@2 {
			reg = <0x02>;
			reg-names = "ion_heap_carveout_mm";
			sprd,ion-heap-type = <0x00>;
			sprd,ion-heap-mem = <0x00 0x00>;
		};

		sprd,ion-heap@3 {
			reg = <0x03>;
			reg-names = "ion_heap_carveout_overlay";
			sprd,ion-heap-type = <0x02>;
			sprd,ion-heap-mem = <0x9f600000 0x500000>;
		};
	};

	sprd_iommu@F5410000 {
		compatible = "sprd,sprd_iommu";
		func-name = "sprd_iommu_gsp";
		reg = <0x10000000 0x2000000 0xf5410000 0x8000 0xf5418000 0x8000>;
		reg_name = "iova\0pgt\0ctrl_reg";
		clock-names = "clk_gsp_emc\0clk_153m6\0clk_gsp";
		clocks = <0x3e 0x0c 0x3d>;
		status = "ok";
	};

	sprd_iommu@F5430000 {
		compatible = "sprd,sprd_iommu";
		func-name = "sprd_iommu_mm";
		reg = <0x20000000 0x8000000 0xf5430000 0x20000 0xf5450000 0x2000>;
		reg_name = "iova\0pgt\0ctrl_reg";
		clock-names = "clk_mmu\0clk_mm_i";
		clocks = <0x4a 0x22>;
		status = "ok";
	};

	sipc-common {
		compatible = "sprd,sipc";
		#address-cells = <0x01>;
		#size-cells = <0x01>;
		reg = <0x87800000 0x240000>;
		ranges = <0x8000000 0x88000000 0x1c00000 0x7800000 0x87800000 0x180000 0x9bff000 0x89bff000 0x1000>;

		sipc_cpw {
			sprd,name = "sipc-w";
			sprd,dst = <0x02>;
			sprd,ap2cp = <0xf5240000>;
			sprd,cp2ap = <0xf5240004>;
			sprd,trig = <0x01>;
			sprd,clr = <0x01>;
			interrupts = <0x00 0x44 0x00>;
			reg = <0x8000000 0x1c00000 0x7800000 0x180000 0x9bff000 0x1000>;
		};
	};

	spipe-cpw {
		compatible = "sprd,spipe";
		sprd,name = "spipe_w";
		sprd,dst = <0x02>;
		sprd,channel = <0x04>;
		sprd,ringnr = <0x09>;
		sprd,size-rxbuf = <0x1000>;
		sprd,size-txbuf = <0x1000>;
	};

	slog-cpw {
		compatible = "sprd,spipe";
		sprd,name = "slog_w";
		sprd,dst = <0x02>;
		sprd,channel = <0x05>;
		sprd,ringnr = <0x01>;
		sprd,size-rxbuf = <0x40000>;
		sprd,size-txbuf = <0x8000>;
	};

	stty-cpw {
		compatible = "sprd,spipe";
		sprd,name = "stty_w";
		sprd,dst = <0x02>;
		sprd,channel = <0x06>;
		sprd,ringnr = <0x20>;
		sprd,size-rxbuf = <0x800>;
		sprd,size-txbuf = <0x800>;
	};

	seth0-cpw {
		compatible = "sprd,seth";
		sprd,name = "seth_w0";
		sprd,dst = <0x02>;
		sprd,channel = <0x07>;
		sprd,blknum = <0x80>;
	};

	seth1-cpw {
		compatible = "sprd,seth";
		sprd,name = "seth_w1";
		sprd,dst = <0x02>;
		sprd,channel = <0x08>;
		sprd,blknum = <0x40>;
	};

	seth2-cpw {
		compatible = "sprd,seth";
		sprd,name = "seth_w2";
		sprd,dst = <0x02>;
		sprd,channel = <0x09>;
		sprd,blknum = <0x40>;
	};

	scproc {
		compatible = "sprd,scproc";
		sprd,name = "cpw";
		sprd,ctrl-reg = <0x44 0x44 0xb0 0xbc>;
		sprd,ctrl-mask = <0x2000000 0x10000000 0x01 0xf0000>;
		interrupts = <0x00 0x54 0x00>;
		#address-cells = <0x01>;
		#size-cells = <0x01>;
		sprd,iram-data = <0xe59f0000 0xe12fff10 0x88300000>;
		reg = <0x88000000 0x1c00000 0xf53d4000 0x0c 0xf5230000 0x10000>;
		ranges = <0x300000 0x88300000 0x800000 0x20000 0x88020000 0x220000>;

		modem {
			cproc,name = "modem";
			reg = <0x300000 0x800000>;
		};

		dsp {
			cproc,name = "dsp";
			reg = <0x20000 0x220000>;
		};
	};

	saudio_w {
		compatible = "sprd,saudio";
		sprd,saudio-dst-id = <0x02>;
		sprd,saudio-names = "saudio_w";
	};

	saudio_voip {
		compatible = "sprd,saudio";
		sprd,saudio-dst-id = <0x02>;
		sprd,saudio-names = "saudio_voip";
	};

	cpus {
		#address-cells = <0x01>;
		#size-cells = <0x00>;

		cpu@f00 {
			device_type = "cpu";
			compatible = "arm,cortex-a7";
			reg = <0xf00>;
		};

		cpu@f01 {
			device_type = "cpu";
			compatible = "arm,cortex-a7";
			reg = <0xf01>;
		};

		cpu@f02 {
			device_type = "cpu";
			compatible = "arm,cortex-a7";
			reg = <0xf02>;
		};

		cpu@f03 {
			device_type = "cpu";
			compatible = "arm,cortex-a7";
			reg = <0xf03>;
		};
	};

	gpu {
		compatible = "sprd,mali-utgard";
		mali_pp_core_number = <0x04>;
		interrupt-names = "mali_gp_irq\0mali_gp_mmu_irq\0mali_pp0_irq\0mali_pp0_mmu_irq\0mali_pp1_irq\0mali_pp1_mmu_irq";
		reg-names = "mali_l2\0mali_gp\0mali_gp_mmu\0mali_pp0\0mali_pp0_mmu\0mali_pp1\0mali_pp1_mmu\0mali_pmu";
		interrupts = <0x00 0x27 0x00 0x00 0x27 0x00 0x00 0x27 0x00 0x00 0x27 0x00 0x00 0x27 0x00 0x00 0x27 0x00>;
		reg = <0x60001000 0x200 0x60000000 0x100 0x60003000 0x100 0x60008000 0x1100 0x60004000 0x100 0x6000a000 0x1100 0x60005000 0x100 0x60002000 0x100>;
		clock-names = "clk_gpu_axi\0clk_gpu\0clk_153m6\0clk_208m\0clk_256m\0clk_312m\0clk_384m\0clk_460m8";
		clocks = <0x4b 0x4c 0x0c 0x1d 0x1a 0x1b 0x1c 0x21>;
	};

	pmu {
		compatible = "arm,cortex-a7-pmu";
		interrupts = <0x00 0x5c 0x400 0x00 0x5d 0x400 0x00 0x5e 0x400 0x00 0x5f 0x400>;
	};

	gpio_keys {
		compatible = "gpio-keys";

		home {
			label = "Home Key";
			linux,code = <0x66>;
			gpio = <0x34 0x71 0x01>;
			debounce-interval = <0x02>;
			gpio-key,wakeup;
		};
	};

	bcm-bt-rfkill {
		compatible = "bcm,bcm-bt-rfkill";
		gpios = <0x34 0xe7 0x00 0x34 0xe9 0x00>;
	};

	bcm-bt-lpm {
		compatible = "bcm,bcm-bt-lpm";
		gpios = <0x34 0xe8 0x00 0x34 0xeb 0x00>;
	};

	gps {
		compatible = "broadcom,bcm47520";
		gps-pwr-en = <0x34 0xa8 0x00>;
	};

	gps_2351@21c00000 {
		compatible = "sprd,gps_2351";
		interrupts = <0x00 0x34 0x00>;
		gpios = <0x34 0x32 0x00>;
		reg = <0xf5150000 0x1000 0xf5130000 0x10000 0xf5230000 0x10000>;
	};

	i2c_gpio@1 {
		compatible = "i2c-gpio";
		#address-cells = <0x01>;
		#size-cells = <0x00>;
		gpios = <0x34 0x9f 0x00 0x34 0xa0 0x00>;
		i2c-gpio,delay-us = <0x0a>;
		i2c-gpio,timeout-ms = <0x00>;
		status = "okay";

		smb328-i2c@34 {
			compatible = "QC,smb328";
			reg = <0x34>;
			chgirq-gpio = <0x34 0xa1 0x00>;
			chgen-gpio = <0x34 0xd7 0x00>;
			chg-float-voltage = <0x10f4>;
		};
	};

	i2c_gpio@2 {
		compatible = "i2c-gpio";
		#address-cells = <0x01>;
		#size-cells = <0x00>;
		gpios = <0x34 0x96 0x00 0x34 0x97 0x00>;
		i2c-gpio,delay-us = <0x0a>;
		i2c-gpio,timeout-ms = <0x00>;

		sm5504@14 {
			compatible = "SiliconMitus,sm5504";
			reg = <0x14>;
			interrupt-parent = <0x34>;
			sm5504,irq-gpio = <0x34 0x95 0x00>;
		};
	};

	sec_thermistor {
		compatible = "sec,thermistor";
	};

	sec-fuelgauge {
		compatible = "samsung,sec-fuelgauge";
		capacity-max = <0x3e8>;
		capacity-max-margin = <0x3e8>;
		capacity-min = <0x0a>;
		fg-irq-attr = <0x00>;
		fuel-alert-soc = <0x3e8>;
		temp_adc_channel = <0x00>;
		chg_bat_safety_vol = <0x11f8>;
		gpios = <0x33 0x00 0x00>;
		soft_vbat_uvlo = <0xbea>;
		vmode = <0x00>;
		alm_soc = <0x05>;
		alm_vbat = <0xdac>;
		rint = <0xfa>;
		cnom = <0xe10>;
		rsense_real = <0xcb>;
		rsense_spec = <0xc8>;
		relax_current = <0x32>;
		ocv_table = <0x10f7 0x64 0x10bd 0x5f 0x1087 0x5a 0x1053 0x55 0x1020 0x50 0xff0 0x4b 0xfc3 0x46 0xf8f 0x41 0xf6d 0x3c 0xf38 0x37 0xf15 0x32 0xefc 0x2d 0xee8 0x28 0xed6 0x23 0xec9 0x1e 0xebd 0x19 0xead 0x14 0xe96 0x0f 0xe6e 0x0a 0xe68 0x05 0xd48 0x00>;

		sprd_fgu {
			compatible = "sprd,sprd_fgu";
			interrupt-parent = <0x32>;
			interrupts = <0x04 0x00>;
		};
	};

	sec-battery {
		compatible = "samsung,sec-battery";
		battery,vendor = "SDI SDI";
		battery,charger_name = "sec-charger";
		battery,fuelgauge_name = "sec-fuelgauge";
		battery,technology = <0x02>;
		battery,chip_vendor = "SPRD";
		battery,temp_adc_type = <0x01>;
		battery,polling_time = <0x0a 0x1e 0x1e 0x1e 0xe10>;
		battery,adc_check_count = <0x05>;
		battery,cable_check_type = <0x05>;
		battery,cable_source_type = <0x03>;
		battery,event_waiting_time = <0x258>;
		battery,polling_type = <0x01>;
		battery,monitor_initial_count = <0x03>;
		battery,battery_check_type = <0x00>;
		battery,check_count = <0x00>;
		battery,check_adc_max = <0x5a0>;
		battery,check_adc_min = <0x00>;
		battery,ovp_uvlo_check_type = <0x03>;
		battery,thermal_source = <0x02>;
		battery,temp_table_adc = <0x29b 0x384 0x49c 0x546 0x61b 0x7b4 0x956 0xac8 0xbea 0xc80 0xd20 0xdd1>;
		battery,temp_table_data = <0x2bc 0x258 0x1f4 0x1c2 0x190 0x12c 0xc8 0x64 0x00 0xffffffce 0xffffff9c 0xffffff38>;
		battery,temp_check_type = <0x02>;
		battery,temp_check_count = <0x01>;
		battery,temp_high_threshold_event = <0x226>;
		battery,temp_high_recovery_event = <0x1c2>;
		battery,temp_low_threshold_event = <0xffffffce>;
		battery,temp_low_recovery_event = <0x00>;
		battery,temp_high_threshold_normal = <0x226>;
		battery,temp_high_recovery_normal = <0x1c2>;
		battery,temp_low_threshold_normal = <0xffffffce>;
		battery,temp_low_recovery_normal = <0x00>;
		battery,temp_high_threshold_lpm = <0x226>;
		battery,temp_high_recovery_lpm = <0x1c2>;
		battery,temp_low_threshold_lpm = <0xffffffce>;
		battery,temp_low_recovery_lpm = <0x00>;
		battery,full_check_type = <0x07>;
		battery,full_check_type_2nd = <0x03>;
		battery,full_check_count = <0x01>;
		battery,chg_gpio_full_check = <0x00>;
		battery,chg_polarity_full_check = <0x01>;
		battery,full_condition_type = <0x0d>;
		battery,full_condition_soc = <0x5f>;
		battery,full_condition_vcell = <0x109a>;
		battery,recharge_check_count = <0x01>;
		battery,recharge_condition_type = <0x04>;
		battery,recharge_condition_soc = <0x62>;
		battery,recharge_condition_vcell = <0x10cc>;
		battery,charging_total_time = <0x5460>;
		battery,recharging_total_time = <0x1518>;
		battery,charging_reset_time = <0x00>;
		charger,vbus_ctrl_gpio = <0x34 0x40 0x00>;
		battery,input_current_limit = <0x3e8 0x226 0x226 0x3e8 0x226 0x3e8 0x3e8 0x226 0x226 0x3e8 0x28a 0x3e8 0x3e8 0x226 0x3e8 0x12c 0x3e8 0x3e8 0x12c 0x3e8 0x3e8 0x226 0x226>;
		battery,fast_charging_current = <0x60e 0x00 0x1f4 0x60e 0x1f4 0x60e 0x60e 0x1f4 0x00 0x60e 0x60e 0x60e 0x60e 0xffffffff 0x60e 0x12c 0x60e 0x60e 0x12c 0x60e 0x60e 0x00 0x00>;
		battery,full_check_current_1st = <0xc8 0x00 0xc8 0xc8 0xc8 0xc8 0xc8 0xc8 0x00 0xc8 0xc8 0xc8 0xc8 0x00 0xc8 0xc8 0xc8 0xc8 0xc8 0xc8 0xc8 0x00 0x00>;
		battery,full_check_current_2nd = <0x4b0 0x00 0x4b0 0x4b0 0x4b0 0x4b0 0x4b0 0x4b0 0x00 0x4b0 0x4b0 0x4b0 0x4b0 0x00 0x4b0 0x4b0 0x4b0 0x4b0 0x4b0 0x4b0 0x4b0 0x00 0x00>;
	};

	isdbt_data {
		compatible = "isdbt_pdata";
		isdbt_spi_mosi = <0x34 0x44 0x00>;
		isdbt_spi_miso = <0x34 0x45 0x00>;
		isdbt_spi_cs = <0x34 0x43 0x00>;
		isdbt_spi_clk = <0x34 0x46 0x00>;
		isdbt_pwr_en = <0x34 0x51 0x00>;
		isdbt_irq = <0x34 0xa5 0x00>;
	};

	gen-panel-backlight {
		compatible = "gen-panel-backlight";
		gen-panel-backlight-name = "panel";
		gen-panel-backlight-brt-range = <0x00 0x00 0x05 0x28 0x05 0x28 0xa2 0x3e0 0xff 0x7f8>;
		linux,phandle = <0x4e>;
		phandle = <0x4e>;
	};

	panel {
		compatible = "sprd,sprdfb-i2c-panel";
		pinctrl-names = "default";
		gen-panel = <0x4d>;
		gen-panel-backlight = <0x4e>;

		panel-ext-pin {
			panel-ext-pin-on = <0x4f 0x01 0x3e8 0x50 0x01 0x00 0x51 0x01 0x14 0x52 0x00 0x14 0x52 0x01 0x14 0x53 0x01 0x00>;
			panel-ext-pin-off = <0x53 0x00 0x00 0x52 0x00 0x14 0x51 0x00 0x14 0x50 0x00 0x00 0x4f 0x00 0x00>;

			panel-ext-pin-0 {
				pin-name = "bridge_en";
				pin-type = <0x00>;
				pin-gpio = <0x34 0xe9 0x00>;
				linux,phandle = <0x4f>;
				phandle = <0x4f>;
			};

			panel-ext-pin-1 {
				pin-name = "bridge_rst";
				pin-type = <0x00>;
				pin-gpio = <0x34 0xea 0x01>;
				linux,phandle = <0x52>;
				phandle = <0x52>;
			};

			panel-ext-pin-2 {
				pin-name = "blic_en";
				pin-type = <0x00>;
				pin-gpio = <0x34 0xd6 0x00>;
				linux,phandle = <0x53>;
				phandle = <0x53>;
			};

			panel-ext-pin-3 {
				pin-name = "lvds_1v8";
				pin-type = <0x01>;
				pin-supply = <0x54>;
				linux,phandle = <0x50>;
				phandle = <0x50>;
			};

			panel-ext-pin-4 {
				pin-name = "lvds_3v3";
				pin-type = <0x01>;
				pin-supply = <0x55>;
				linux,phandle = <0x51>;
				phandle = <0x51>;
			};
		};

		gen-panel {
			linux,phandle = <0x4d>;
			phandle = <0x4d>;

			gen-panel-vx5b3d-WSVGA-video {
				gen-panel-manu = "BOE";
				gen-panel-name = "vx5b3d";
				gen-panel-model = "BA070WS1-400";
				gen-panel-id = <0x5b3d>;
				gen-panel-dev-id = <0x00>;
				gen-panel-type = <0x02>;
				gen-panel-refresh = <0x3c>;
				gen-panel-xres = <0x400>;
				gen-panel-yres = <0x258>;
				gen-panel-width = <0x9a>;
				gen-panel-height = <0x5a>;
				gen-panel-work-mode = <0x01>;
				gen-panel-direction = <0x00>;
				gen-panel-suspend-mode = <0x01>;
				gen-panel-bus-width = <0x18>;
				gen-panel-lan-number = <0x04>;
				gen-panel-phy-feq = <0x4c2c0>;
				gen-panel-h-sync-pol = <0x00>;
				gen-panel-v-sync-pol = <0x00>;
				gen-panel-de-pol = <0x00>;
				gen-panel-te-pol = <0x00>;
				gen-panel-color-mode-pol = <0x01>;
				gen-panel-shut-down-pol = <0x01>;
				gen-panel-h-front-porch = <0xa0>;
				gen-panel-h-back-porch = <0x94>;
				gen-panel-h-sync-width = <0x02>;
				gen-panel-v-front-porch = <0x28>;
				gen-panel-v-back-porch = <0x1c>;
				gen-panel-v-sync-width = <0x0a>;
				gen-panel-pkt-dinfo-addr-offset = <0x05>;
				gen-panel-pkt-dinfo-addr-length = <0x02>;
				gen-panel-pkt-dinfo-data-offset = <0x07>;
				gen-panel-pkt-dinfo-data-length = <0x04>;
				gen-panel-init-cmds = [29 00 00 00 00 0b 09 29 05 01 40 00 07 40 00 90 6c 29 00 00 00 00 0b 09 29 05 01 40 04 07 0a 04 03 00 29 00 00 00 00 0b 09 29 05 01 40 0c 07 04 46 00 00 29 00 00 00 00 0b 09 29 05 01 40 10 07 0b 00 4d 05 29 00 00 00 00 0b 09 29 05 01 40 14 07 20 00 00 00 29 00 00 00 00 0b 09 29 05 01 40 18 07 02 01 00 00 29 00 00 00 00 0b 09 29 05 01 40 1c 07 2f 00 a8 00 29 00 00 0a 00 0b 09 29 05 01 40 20 07 00 00 00 00 29 00 00 00 00 0b 09 29 05 01 40 54 01 00 00 00 00 29 00 00 0a 00 0b 09 29 05 01 40 54 01 00 00 00 80 29 00 00 00 00 0b 09 29 05 01 40 00 07 40 08 90 6c 29 00 00 00 00 0b 09 29 05 01 40 0c 07 56 5e 00 00 29 00 00 00 00 0b 09 29 05 01 40 18 07 02 02 00 00 29 00 00 00 00 0b 09 29 05 01 40 54 01 00 00 00 00 29 00 00 0a 00 0b 09 29 05 01 40 54 01 00 00 00 80 29 00 00 00 00 0b 09 29 05 01 40 7c 03 63 10 00 00 29 00 00 00 00 0b 09 29 05 01 40 80 03 30 60 a8 82 29 00 00 00 00 0b 09 29 05 01 40 84 03 8b 40 61 28 29 00 00 00 00 0b 09 29 05 01 40 88 03 85 02 13 00 29 00 00 00 00 0b 09 29 05 01 40 8c 03 09 00 63 10 29 00 00 00 00 0b 09 29 05 01 40 94 03 a8 82 0b 40 29 00 00 00 00 0b 09 29 05 01 40 00 06 8c c7 6c 01 29 00 00 00 00 0b 09 29 05 01 40 04 06 ff ff ff 3f 29 00 00 00 00 0b 09 29 05 01 40 08 06 8c 0d 00 00 29 00 00 00 00 0b 09 29 05 01 40 54 01 00 00 00 00 29 00 00 00 00 0b 09 29 05 01 40 54 01 00 00 00 80 29 00 00 00 00 0b 09 29 05 01 40 20 01 05 00 00 00 29 00 00 00 00 0b 09 29 05 01 40 24 01 00 c4 92 18 29 00 00 00 00 0b 09 29 05 01 40 28 01 06 28 10 00 29 00 00 00 00 0b 09 29 05 01 40 2c 01 62 00 00 00 29 00 00 00 00 0b 09 29 05 01 40 30 01 18 3c 00 00 29 00 00 00 00 0b 09 29 05 01 40 34 01 15 00 00 00 29 00 00 00 00 0b 09 29 05 01 40 38 01 00 80 ff 00 29 00 00 00 00 0b 09 29 05 01 40 3c 01 00 00 00 00 29 00 00 00 00 0b 09 29 05 01 40 14 01 02 63 0c 00 29 00 00 00 00 0b 09 29 05 01 40 40 01 00 00 01 00 29 00 00 00 00 0b 09 29 05 01 40 74 01 00 00 00 00 29 00 00 00 00 0b 09 29 05 01 40 04 04 22 08 55 55 29 00 00 00 00 0b 09 29 05 01 40 18 04 ff 02 55 55 29 00 00 00 00 0b 09 29 05 01 40 10 04 00 03 e5 05 29 00 00 00 00 0b 09 29 05 01 40 0c 02 24 01 00 00 29 00 00 00 00 0b 09 29 05 01 40 1c 02 00 00 00 00 29 00 00 00 00 0b 09 29 05 01 40 24 02 07 00 00 00 29 00 00 00 00 0b 09 29 05 01 40 28 02 01 00 05 00 29 00 00 00 00 0b 09 29 05 01 40 2c 02 03 ff 00 00 29 00 00 00 00 0b 09 29 05 01 40 30 02 01 00 00 00 29 00 00 00 00 0b 09 29 05 01 40 34 02 10 3e 03 ca 29 00 00 00 00 0b 09 29 05 01 40 38 02 60 00 00 00 29 00 00 00 00 0b 09 29 05 01 40 3c 02 30 60 e8 82 29 00 00 00 00 0b 09 29 05 01 40 44 02 85 02 1e 00 29 00 00 00 00 0b 09 29 05 01 40 58 02 62 00 06 00 29 00 00 00 00 0b 09 29 05 01 40 00 04 00 00 00 00 29 00 00 00 00 0b 09 29 05 01 40 58 01 00 00 00 00 29 00 00 00 00 0b 09 29 05 01 40 58 01 01 00 00 00];
				gen-panel-enable-cmds;
				gen-panel-disable-cmds = [29 00 00 00 00 0b 09 29 05 01 40 64 01 00 00 00 00 29 00 00 64 00 0b 09 29 05 01 40 5c 01 00 00 00 00 29 00 00 01 00 0b 09 29 05 01 40 04 06 ff ff ff 3f];
				gen-panel-backlight-on-cmds = <0x29000000 0xb0929 0x5014060 0x1f80700 0x290000 0x22000b09 0x29050140 0x406e0ff 0xff3f2900 0x0b 0x9290501 0x40380100 0xff3f29 0x00 0xb092905 0x1405c01 0x5000000>;
				gen-panel-backlight-set-brightness-cmds = [29 00 00 00 00 0b 09 29 05 01 40 64 01 78 04 00 00];
				gen-panel-backlight-set-brightness-reg = <0x164>;
				gen-panel-backlight-get-brightness-reg = <0x164>;
				gen-panel-read-id = [da 00 01 db 00 01 dc 00 01];
				gen-panel-read-status-reg = <0x0a>;
				gen-panel-read-status-ok = <0x9a>;

				gen-panel-manipulate-table {

					manipulate-1 {
						gen-panel-init-cmds = <0x29000000 0xb0929 0x5014004 0x70a0403 0x290000 0xb09 0x29050140 0x240100c4 0x92182900 0x0b 0x9290501 0x402c0162 0x29 0x00 0xb092905 0x1405802 0x62000600>;
						linux,phandle = <0x56>;
						phandle = <0x56>;
					};

					manipulate-2 {
						gen-panel-init-cmds = <0x29000000 0xb0929 0x5014004 0x7490403 0x290000 0xb09 0x29050140 0x240100c4 0x121b2900 0x0b 0x9290501 0x402c016c 0x29 0x00 0xb092905 0x1405802 0x6c000a00>;
						linux,phandle = <0x57>;
						phandle = <0x57>;
					};
				};

				gen-panel-sysfs-node {

					lvds_clk {
						action-names = "4805\05098";
						action-0 = <0x56>;
						action-1 = <0x57>;
					};
				};
			};
		};
	};
};
